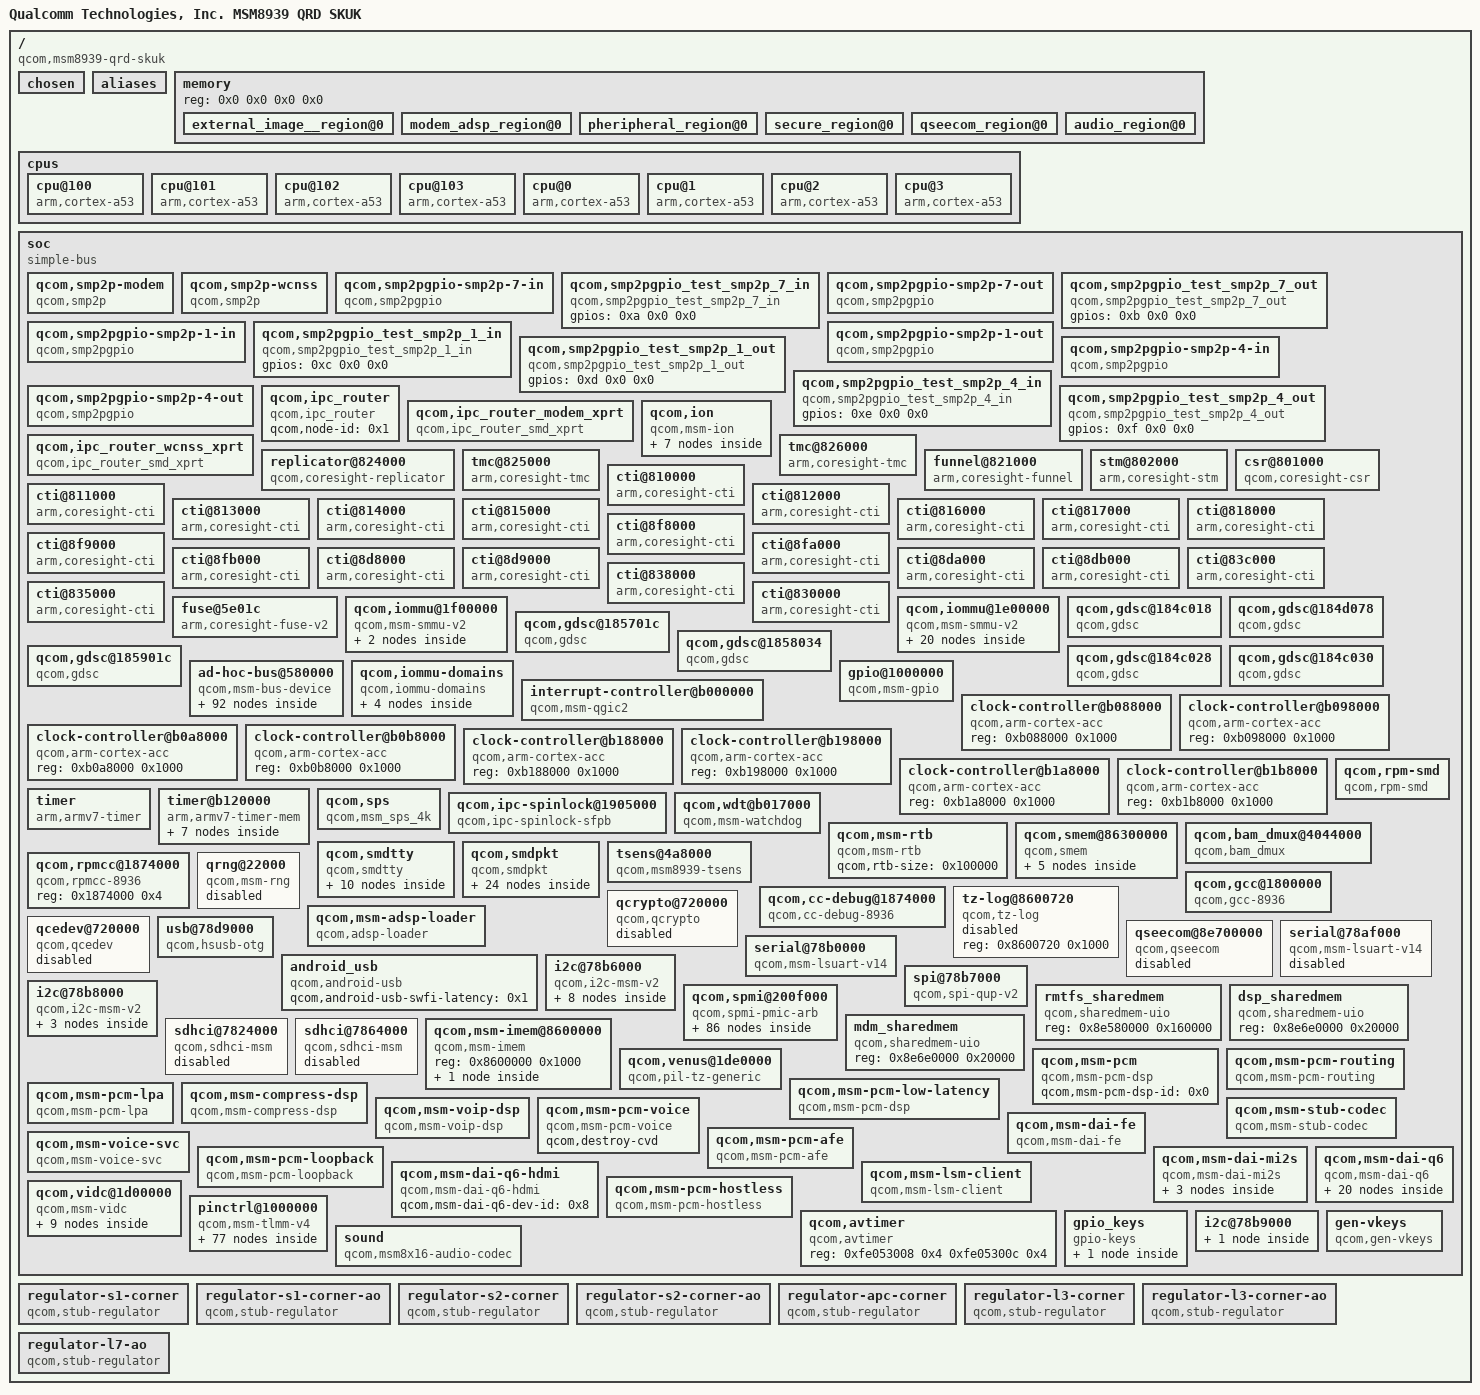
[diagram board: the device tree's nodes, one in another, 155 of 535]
/dts-v1/;

/ {
	#address-cells = <0x2>;
	#size-cells = <0x2>;
	model = "Qualcomm Technologies, Inc. MSM8939 QRD SKUK";
	compatible = "qcom,msm8939-qrd-skuk", "qcom,msm8939-qrd", "qcom,msm8939", "qcom,qrd";
	qcom,msm-id = <0xef 0x0 0xf1 0x0>;
	interrupt-parent = <0x1>;
	qcom,board-id = <0x1000b 0x5>;

	chosen {
	};

	aliases {
		sdhc1 = "/soc/sdhci@7824000";
		sdhc2 = "/soc/sdhci@7864000";
		smd1 = "/soc/qcom,smdtty/qcom,smdtty-apps-fm";
		smd2 = "/soc/qcom,smdtty/smdtty-apps-riva-bt-acl";
		smd3 = "/soc/qcom,smdtty/qcom,smdtty-apps-riva-bt-cmd";
		smd5 = "/soc/qcom,smdtty/smdtty-apps-riva-ant-cmd";
		smd6 = "/soc/qcom,smdtty/smdtty-apps-riva-ant-data";
		smd7 = "/soc/qcom,smdtty/qcom,smdtty-data1";
		smd8 = "/soc/qcom,smdtty/qcom,smdtty-data4";
		smd11 = "/soc/qcom,smdtty/qcom,smdtty-data11";
		smd21 = "/soc/qcom,smdtty/qcom,smdtty-data21";
		smd36 = "/soc/qcom,smdtty/smdtty-loopback";
		i2c0 = "/soc/i2c@78b6000";
		i2c4 = "/soc/i2c@78b8000";
		spi0 = "/soc/spi@78b7000";
	};

	memory {
		device_type = "memory";
		reg = <0x0 0x0 0x0 0x0>;
		#address-cells = <0x2>;
		#size-cells = <0x2>;

		external_image__region@0 {
			linux,reserve-contiguous-region;
			linux,reserve-region;
			linux,remove-completely;
			reg = <0x0 0x8e200000 0x0 0x800000>;
			label = "external_image_mem";
		};

		modem_adsp_region@0 {
			linux,reserve-contiguous-region;
			linux,reserve-region;
			linux,remove-completely;
			reg = <0x0 0x88800000 0x0 0x5a00000>;
			label = "modem_adsp_mem";
			linux,phandle = <0x14>;
			phandle = <0x14>;
		};

		pheripheral_region@0 {
			linux,reserve-contiguous-region;
			linux,reserve-region;
			linux,remove-completely;
			reg = <0x0 0x8ea00000 0x0 0xb00000>;
			label = "peripheral_mem";
			linux,phandle = <0x13>;
			phandle = <0x13>;
		};

		secure_region@0 {
			linux,reserve-contiguous-region;
			reg = <0x0 0x0 0x0 0x6d00000>;
			label = "secure_mem";
			linux,phandle = <0x10>;
			phandle = <0x10>;
		};

		qseecom_region@0 {
			linux,reserve-contiguous-region;
			reg = <0x0 0x0 0x0 0xd00000>;
			label = "qseecom_mem";
			linux,phandle = <0x11>;
			phandle = <0x11>;
		};

		audio_region@0 {
			linux,reserve-contiguous-region;
			reg = <0x0 0x0 0x0 0x314000>;
			label = "audio_mem";
			linux,phandle = <0x12>;
			phandle = <0x12>;
		};
	};

	cpus {
		#address-cells = <0x1>;
		#size-cells = <0x0>;

		cpu@100 {
			device_type = "cpu";
			compatible = "arm,cortex-a53";
			reg = <0x100>;
			enable-method = "qcom,arm-cortex-acc";
			qcom,acc = <0x2>;
		};

		cpu@101 {
			device_type = "cpu";
			compatible = "arm,cortex-a53";
			reg = <0x101>;
			enable-method = "qcom,arm-cortex-acc";
			qcom,acc = <0x3>;
		};

		cpu@102 {
			device_type = "cpu";
			compatible = "arm,cortex-a53";
			reg = <0x102>;
			enable-method = "qcom,arm-cortex-acc";
			qcom,acc = <0x4>;
		};

		cpu@103 {
			device_type = "cpu";
			compatible = "arm,cortex-a53";
			reg = <0x103>;
			enable-method = "qcom,arm-cortex-acc";
			qcom,acc = <0x5>;
		};

		cpu@0 {
			device_type = "cpu";
			compatible = "arm,cortex-a53";
			reg = <0x0>;
			enable-method = "qcom,arm-cortex-acc";
			qcom,acc = <0x6>;
		};

		cpu@1 {
			device_type = "cpu";
			compatible = "arm,cortex-a53";
			reg = <0x1>;
			enable-method = "qcom,arm-cortex-acc";
			qcom,acc = <0x7>;
		};

		cpu@2 {
			device_type = "cpu";
			compatible = "arm,cortex-a53";
			reg = <0x2>;
			enable-method = "qcom,arm-cortex-acc";
			qcom,acc = <0x8>;
		};

		cpu@3 {
			device_type = "cpu";
			compatible = "arm,cortex-a53";
			reg = <0x3>;
			enable-method = "qcom,arm-cortex-acc";
			qcom,acc = <0x9>;
		};
	};

	soc {
		#address-cells = <0x1>;
		#size-cells = <0x1>;
		ranges = <0x0 0x0 0x0 0xffffffff>;
		compatible = "simple-bus";

		qcom,smp2p-modem {
			compatible = "qcom,smp2p";
			reg = <0xb111008 0x4>;
			qcom,remote-pid = <0x1>;
			qcom,irq-bitmask = <0x4000>;
			interrupts = <0x0 0x1b 0x1>;
		};

		qcom,smp2p-wcnss {
			compatible = "qcom,smp2p";
			reg = <0xb111008 0x4>;
			qcom,remote-pid = <0x4>;
			qcom,irq-bitmask = <0x40000>;
			interrupts = <0x0 0x8f 0x1>;
		};

		qcom,smp2pgpio-smp2p-7-in {
			compatible = "qcom,smp2pgpio";
			qcom,entry-name = "smp2p";
			qcom,remote-pid = <0x7>;
			qcom,is-inbound;
			gpio-controller;
			#gpio-cells = <0x2>;
			interrupt-controller;
			#interrupt-cells = <0x2>;
			linux,phandle = <0xa>;
			phandle = <0xa>;
		};

		qcom,smp2pgpio_test_smp2p_7_in {
			compatible = "qcom,smp2pgpio_test_smp2p_7_in";
			gpios = <0xa 0x0 0x0>;
		};

		qcom,smp2pgpio-smp2p-7-out {
			compatible = "qcom,smp2pgpio";
			qcom,entry-name = "smp2p";
			qcom,remote-pid = <0x7>;
			gpio-controller;
			#gpio-cells = <0x2>;
			interrupt-controller;
			#interrupt-cells = <0x2>;
			linux,phandle = <0xb>;
			phandle = <0xb>;
		};

		qcom,smp2pgpio_test_smp2p_7_out {
			compatible = "qcom,smp2pgpio_test_smp2p_7_out";
			gpios = <0xb 0x0 0x0>;
		};

		qcom,smp2pgpio-smp2p-1-in {
			compatible = "qcom,smp2pgpio";
			qcom,entry-name = "smp2p";
			qcom,remote-pid = <0x1>;
			qcom,is-inbound;
			gpio-controller;
			#gpio-cells = <0x2>;
			interrupt-controller;
			#interrupt-cells = <0x2>;
			linux,phandle = <0xc>;
			phandle = <0xc>;
		};

		qcom,smp2pgpio_test_smp2p_1_in {
			compatible = "qcom,smp2pgpio_test_smp2p_1_in";
			gpios = <0xc 0x0 0x0>;
		};

		qcom,smp2pgpio-smp2p-1-out {
			compatible = "qcom,smp2pgpio";
			qcom,entry-name = "smp2p";
			qcom,remote-pid = <0x1>;
			gpio-controller;
			#gpio-cells = <0x2>;
			interrupt-controller;
			#interrupt-cells = <0x2>;
			linux,phandle = <0xd>;
			phandle = <0xd>;
		};

		qcom,smp2pgpio_test_smp2p_1_out {
			compatible = "qcom,smp2pgpio_test_smp2p_1_out";
			gpios = <0xd 0x0 0x0>;
		};

		qcom,smp2pgpio-smp2p-4-in {
			compatible = "qcom,smp2pgpio";
			qcom,entry-name = "smp2p";
			qcom,remote-pid = <0x4>;
			qcom,is-inbound;
			gpio-controller;
			#gpio-cells = <0x2>;
			interrupt-controller;
			#interrupt-cells = <0x2>;
			linux,phandle = <0xe>;
			phandle = <0xe>;
		};

		qcom,smp2pgpio_test_smp2p_4_in {
			compatible = "qcom,smp2pgpio_test_smp2p_4_in";
			gpios = <0xe 0x0 0x0>;
		};

		qcom,smp2pgpio-smp2p-4-out {
			compatible = "qcom,smp2pgpio";
			qcom,entry-name = "smp2p";
			qcom,remote-pid = <0x4>;
			gpio-controller;
			#gpio-cells = <0x2>;
			interrupt-controller;
			#interrupt-cells = <0x2>;
			linux,phandle = <0xf>;
			phandle = <0xf>;
		};

		qcom,smp2pgpio_test_smp2p_4_out {
			compatible = "qcom,smp2pgpio_test_smp2p_4_out";
			gpios = <0xf 0x0 0x0>;
		};

		qcom,ipc_router {
			compatible = "qcom,ipc_router";
			qcom,node-id = <0x1>;
		};

		qcom,ipc_router_modem_xprt {
			compatible = "qcom,ipc_router_smd_xprt";
			qcom,ch-name = "IPCRTR";
			qcom,xprt-remote = "modem";
			qcom,xprt-linkid = <0x1>;
			qcom,xprt-version = <0x1>;
			qcom,fragmented-data;
		};

		qcom,ipc_router_wcnss_xprt {
			compatible = "qcom,ipc_router_smd_xprt";
			qcom,ch-name = "IPCRTR";
			qcom,xprt-remote = "wcnss";
			qcom,xprt-linkid = <0x1>;
			qcom,xprt-version = <0x1>;
			qcom,fragmented-data;
		};

		qcom,ion {
			compatible = "qcom,msm-ion";
			#address-cells = <0x1>;
			#size-cells = <0x0>;

			qcom,ion-heap@25 {
				reg = <0x19>;
				qcom,ion-heap-type = "SYSTEM";
			};

			qcom,ion-heap@21 {
				reg = <0x15>;
				qcom,ion-heap-type = "SYSTEM_CONTIG";
			};

			qcom,ion-heap@8 {
				compatible = "qcom,msm-ion-reserve";
				reg = <0x8>;
				qcom,heap-align = <0x1000>;
				linux,contiguous-region = <0x10>;
				qcom,ion-heap-type = "SECURE_DMA";
			};

			qcom,ion-heap@27 {
				compatible = "qcom,msm-ion-reserve";
				reg = <0x1b>;
				linux,contiguous-region = <0x11>;
				qcom,ion-heap-type = "DMA";
			};

			qcom,ion-heap@28 {
				compatible = "qcom,msm-ion-reserve";
				reg = <0x1c>;
				linux,contiguous-region = <0x12>;
				qcom,ion-heap-type = "DMA";
			};

			qcom,ion-heap@23 {
				compatible = "qcom,msm-ion-reserve";
				reg = <0x17>;
				linux,contiguous-region = <0x13>;
				qcom,ion-heap-type = "DMA";
			};

			qcom,ion-heap@26 {
				compatible = "qcom,msm-ion-reserve";
				reg = <0x1a>;
				linux,contiguous-region = <0x14>;
				qcom,ion-heap-type = "DMA";
			};
		};

		tmc@826000 {
			compatible = "arm,coresight-tmc";
			reg = <0x826000 0x1000 0x884000 0x15000>;
			reg-names = "tmc-base", "bam-base";
			interrupts = <0x0 0xa6 0x0>;
			interrupt-names = "byte-cntr-irq";
			qcom,memory-size = <0x100000>;
			coresight-id = <0x0>;
			coresight-name = "coresight-tmc-etr";
			coresight-nr-inports = <0x1>;
			coresight-ctis = <0x15 0x16>;
			clocks = <0x17 0x1492202a 0x17 0xdd121669>;
			clock-names = "core_clk", "core_a_clk";
			linux,phandle = <0x18>;
			phandle = <0x18>;
		};

		replicator@824000 {
			compatible = "qcom,coresight-replicator";
			reg = <0x824000 0x1000>;
			reg-names = "replicator-base";
			coresight-id = <0x1>;
			coresight-name = "coresight-replicator";
			coresight-nr-inports = <0x1>;
			coresight-outports = <0x0>;
			coresight-child-list = <0x18>;
			coresight-child-ports = <0x0>;
			clocks = <0x17 0x1492202a 0x17 0xdd121669>;
			clock-names = "core_clk", "core_a_clk";
			linux,phandle = <0x19>;
			phandle = <0x19>;
		};

		tmc@825000 {
			compatible = "arm,coresight-tmc";
			reg = <0x825000 0x1000>;
			reg-names = "tmc-base";
			coresight-id = <0x2>;
			coresight-name = "coresight-tmc-etf";
			coresight-nr-inports = <0x1>;
			coresight-outports = <0x0>;
			coresight-child-list = <0x19>;
			coresight-child-ports = <0x0>;
			coresight-default-sink;
			coresight-ctis = <0x15 0x16>;
			clocks = <0x17 0x1492202a 0x17 0xdd121669>;
			clock-names = "core_clk", "core_a_clk";
			linux,phandle = <0x1a>;
			phandle = <0x1a>;
		};

		funnel@821000 {
			compatible = "arm,coresight-funnel";
			reg = <0x821000 0x1000>;
			reg-names = "funnel-base";
			coresight-id = <0x3>;
			coresight-name = "coresight-funnel-in0";
			coresight-nr-inports = <0x8>;
			coresight-outports = <0x0>;
			coresight-child-list = <0x1a>;
			coresight-child-ports = <0x0>;
			clocks = <0x17 0x1492202a 0x17 0xdd121669>;
			clock-names = "core_clk", "core_a_clk";
			linux,phandle = <0x1b>;
			phandle = <0x1b>;
		};

		stm@802000 {
			compatible = "arm,coresight-stm";
			reg = <0x802000 0x1000 0x9280000 0x180000>;
			reg-names = "stm-base", "stm-data-base";
			coresight-id = <0x4>;
			coresight-name = "coresight-stm";
			coresight-nr-inports = <0x0>;
			coresight-outports = <0x0>;
			coresight-child-list = <0x1b>;
			coresight-child-ports = <0x7>;
			clocks = <0x17 0x1492202a 0x17 0xdd121669>;
			clock-names = "core_clk", "core_a_clk";
		};

		csr@801000 {
			compatible = "qcom,coresight-csr";
			reg = <0x801000 0x1000>;
			reg-names = "csr-base";
			coresight-id = <0x5>;
			coresight-name = "coresight-csr";
			coresight-nr-inports = <0x0>;
			qcom,blk-size = <0x1>;
		};

		cti@810000 {
			compatible = "arm,coresight-cti";
			reg = <0x810000 0x1000>;
			reg-names = "cti-base";
			coresight-id = <0x6>;
			coresight-name = "coresight-cti0";
			coresight-nr-inports = <0x0>;
			clocks = <0x17 0x1492202a 0x17 0xdd121669>;
			clock-names = "core_clk", "core_a_clk";
			linux,phandle = <0x15>;
			phandle = <0x15>;
		};

		cti@811000 {
			compatible = "arm,coresight-cti";
			reg = <0x811000 0x1000>;
			reg-names = "cti-base";
			coresight-id = <0x7>;
			coresight-name = "coresight-cti1";
			coresight-nr-inports = <0x0>;
			clocks = <0x17 0x1492202a 0x17 0xdd121669>;
			clock-names = "core_clk", "core_a_clk";
		};

		cti@812000 {
			compatible = "arm,coresight-cti";
			reg = <0x812000 0x1000>;
			reg-names = "cti-base";
			coresight-id = <0x8>;
			coresight-name = "coresight-cti2";
			coresight-nr-inports = <0x0>;
			clocks = <0x17 0x1492202a 0x17 0xdd121669>;
			clock-names = "core_clk", "core_a_clk";
		};

		cti@813000 {
			compatible = "arm,coresight-cti";
			reg = <0x813000 0x1000>;
			reg-names = "cti-base";
			coresight-id = <0x9>;
			coresight-name = "coresight-cti3";
			coresight-nr-inports = <0x0>;
			clocks = <0x17 0x1492202a 0x17 0xdd121669>;
			clock-names = "core_clk", "core_a_clk";
		};

		cti@814000 {
			compatible = "arm,coresight-cti";
			reg = <0x814000 0x1000>;
			reg-names = "cti-base";
			coresight-id = <0xa>;
			coresight-name = "coresight-cti4";
			coresight-nr-inports = <0x0>;
			clocks = <0x17 0x1492202a 0x17 0xdd121669>;
			clock-names = "core_clk", "core_a_clk";
		};

		cti@815000 {
			compatible = "arm,coresight-cti";
			reg = <0x815000 0x1000>;
			reg-names = "cti-base";
			coresight-id = <0xb>;
			coresight-name = "coresight-cti5";
			coresight-nr-inports = <0x0>;
			clocks = <0x17 0x1492202a 0x17 0xdd121669>;
			clock-names = "core_clk", "core_a_clk";
		};

		cti@816000 {
			compatible = "arm,coresight-cti";
			reg = <0x816000 0x1000>;
			reg-names = "cti-base";
			coresight-id = <0xc>;
			coresight-name = "coresight-cti6";
			coresight-nr-inports = <0x0>;
			clocks = <0x17 0x1492202a 0x17 0xdd121669>;
			clock-names = "core_clk", "core_a_clk";
		};

		cti@817000 {
			compatible = "arm,coresight-cti";
			reg = <0x817000 0x1000>;
			reg-names = "cti-base";
			coresight-id = <0xd>;
			coresight-name = "coresight-cti7";
			coresight-nr-inports = <0x0>;
			clocks = <0x17 0x1492202a 0x17 0xdd121669>;
			clock-names = "core_clk", "core_a_clk";
		};

		cti@818000 {
			compatible = "arm,coresight-cti";
			reg = <0x818000 0x1000>;
			reg-names = "cti-base";
			coresight-id = <0xe>;
			coresight-name = "coresight-cti8";
			coresight-nr-inports = <0x0>;
			clocks = <0x17 0x1492202a 0x17 0xdd121669>;
			clock-names = "core_clk", "core_a_clk";
			linux,phandle = <0x16>;
			phandle = <0x16>;
		};

		cti@8f8000 {
			compatible = "arm,coresight-cti";
			reg = <0x8f8000 0x1000>;
			reg-names = "cti-base";
			coresight-id = <0xf>;
			coresight-name = "coresight-cti-perf-cpu0";
			coresight-nr-inports = <0x0>;
			clocks = <0x17 0x1492202a 0x17 0xdd121669>;
			clock-names = "core_clk", "core_a_clk";
		};

		cti@8f9000 {
			compatible = "arm,coresight-cti";
			reg = <0x8f9000 0x1000>;
			reg-names = "cti-base";
			coresight-id = <0x10>;
			coresight-name = "coresight-cti-perf-cpu1";
			coresight-nr-inports = <0x0>;
			clocks = <0x17 0x1492202a 0x17 0xdd121669>;
			clock-names = "core_clk", "core_a_clk";
		};

		cti@8fa000 {
			compatible = "arm,coresight-cti";
			reg = <0x8fa000 0x1000>;
			reg-names = "cti-base";
			coresight-id = <0x11>;
			coresight-name = "coresight-cti-perf-cpu2";
			coresight-nr-inports = <0x0>;
			clocks = <0x17 0x1492202a 0x17 0xdd121669>;
			clock-names = "core_clk", "core_a_clk";
		};

		cti@8fb000 {
			compatible = "arm,coresight-cti";
			reg = <0x8fb000 0x1000>;
			reg-names = "cti-base";
			coresight-id = <0x12>;
			coresight-name = "coresight-cti-perf-cpu3";
			coresight-nr-inports = <0x0>;
			clocks = <0x17 0x1492202a 0x17 0xdd121669>;
			clock-names = "core_clk", "core_a_clk";
		};

		cti@8d8000 {
			compatible = "arm,coresight-cti";
			reg = <0x8d8000 0x1000>;
			reg-names = "cti-base";
			coresight-id = <0x13>;
			coresight-name = "coresight-cti-pow-cpu0";
			coresight-nr-inports = <0x0>;
			clocks = <0x17 0x1492202a 0x17 0xdd121669>;
			clock-names = "core_clk", "core_a_clk";
		};

		cti@8d9000 {
			compatible = "arm,coresight-cti";
			reg = <0x8d9000 0x1000>;
			reg-names = "cti-base";
			coresight-id = <0x14>;
			coresight-name = "coresight-cti-pow-cpu1";
			coresight-nr-inports = <0x0>;
			clocks = <0x17 0x1492202a 0x17 0xdd121669>;
			clock-names = "core_clk", "core_a_clk";
		};

		cti@8da000 {
			compatible = "arm,coresight-cti";
			reg = <0x8da000 0x1000>;
			reg-names = "cti-base";
			coresight-id = <0x15>;
			coresight-name = "coresight-cti-pow-cpu2";
			coresight-nr-inports = <0x0>;
			clocks = <0x17 0x1492202a 0x17 0xdd121669>;
			clock-names = "core_clk", "core_a_clk";
		};

		cti@8db000 {
			compatible = "arm,coresight-cti";
			reg = <0x8db000 0x1000>;
			reg-names = "cti-base";
			coresight-id = <0x16>;
			coresight-name = "coresight-cti-pow-cpu3";
			coresight-nr-inports = <0x0>;
			clocks = <0x17 0x1492202a 0x17 0xdd121669>;
			clock-names = "core_clk", "core_a_clk";
		};

		cti@83c000 {
			compatible = "arm,coresight-cti";
			reg = <0x83c000 0x1000>;
			reg-names = "cti-base";
			coresight-id = <0x17>;
			coresight-name = "coresight-cti-rpm-cpu0";
			coresight-nr-inports = <0x0>;
			clocks = <0x17 0x1492202a 0x17 0xdd121669>;
			clock-names = "core_clk", "core_a_clk";
		};

		cti@838000 {
			compatible = "arm,coresight-cti";
			reg = <0x838000 0x1000>;
			reg-names = "cti-base";
			coresight-id = <0x18>;
			coresight-name = "coresight-cti-modem-cpu0";
			coresight-nr-inports = <0x0>;
			clocks = <0x17 0x1492202a 0x17 0xdd121669>;
			clock-names = "core_clk", "core_a_clk";
		};

		cti@835000 {
			compatible = "arm,coresight-cti";
			reg = <0x835000 0x1000>;
			reg-names = "cti-base";
			coresight-id = <0x19>;
			coresight-name = "coresight-cti-wcn-cpu0";
			coresight-nr-inports = <0x0>;
			clocks = <0x17 0x1492202a 0x17 0xdd121669>;
			clock-names = "core_clk", "core_a_clk";
		};

		cti@830000 {
			compatible = "arm,coresight-cti";
			reg = <0x830000 0x1000>;
			reg-names = "cti-base";
			coresight-id = <0x1a>;
			coresight-name = "coresight-cti-video-cpu0";
			coresight-nr-inports = <0x0>;
			clocks = <0x17 0x1492202a 0x17 0xdd121669>;
			clock-names = "core_clk", "core_a_clk";
		};

		fuse@5e01c {
			compatible = "arm,coresight-fuse-v2";
			reg = <0x5e01c 0x8>;
			reg-names = "fuse-base";
			coresight-id = <0x1b>;
			coresight-name = "coresight-fuse";
			coresight-nr-inports = <0x0>;
		};

		qcom,iommu@1f00000 {
			compatible = "qcom,msm-smmu-v2", "qcom,msm-mmu-500";
			#address-cells = <0x1>;
			#size-cells = <0x1>;
			ranges;
			reg = <0x1f00000 0x10000>;
			reg-names = "iommu_base";
			interrupts = <0x0 0x2b 0x0 0x0 0x2a 0x0>;
			interrupt-names = "global_cfg_NS_irq", "global_cfg_S_irq";
			label = "gfx_iommu";
			qcom,iommu-secure-id = <0x12>;
			clocks = <0x1c 0x75eaefa5 0x1c 0x59505e55>;
			clock-names = "iface_clk", "core_clk";
			status = "ok";

			qcom,iommu-ctx@1f09000 {
				compatible = "qcom,msm-smmu-v2-ctx";
				reg = <0x1f09000 0x1000>;
				interrupts = <0x0 0xf1 0x0>;
				qcom,iommu-ctx-sids = <0x0>;
				label = "gfx3d_user";
			};

			qcom,iommu-ctx@1f0a000 {
				compatible = "qcom,msm-smmu-v2-ctx";
				reg = <0x1f0a000 0x1000>;
				interrupts = <0x0 0xf2 0x0>;
				qcom,iommu-ctx-sids = <0x1>;
				label = "gfx3d_priv";
			};
		};

		qcom,iommu@1e00000 {
			compatible = "qcom,msm-smmu-v2", "qcom,msm-mmu-500";
			#address-cells = <0x1>;
			#size-cells = <0x1>;
			ranges;
			reg = <0x1e00000 0x40000>;
			reg-names = "iommu_base";
			interrupts = <0x0 0x2b 0x0 0x0 0x2a 0x0>;
			interrupt-names = "global_cfg_NS_irq", "global_cfg_S_irq";
			label = "apps_iommu";
			qcom,iommu-secure-id = <0x11>;
			clocks = <0x1c 0x75eaefa5 0x1c 0xaf56a329>;
			clock-names = "iface_clk", "core_clk";
			qcom,cb-base-offset = <0x20000>;
			status = "ok";

			qcom,iommu-ctx@1e22000 {
				compatible = "qcom,msm-smmu-v2-ctx";
				reg = <0x1e22000 0x1000>;
				interrupts = <0x0 0x35 0x0>;
				qcom,iommu-ctx-sids = <0x2000>;
				label = "jpeg_enc0";
			};

			qcom,iommu-ctx@1e23000 {
				compatible = "qcom,msm-smmu-v2-ctx";
				reg = <0x1e23000 0x1000>;
				interrupts = <0x0 0x36 0x0>;
				qcom,iommu-ctx-sids = <0x400>;
				label = "vfe";
			};

			qcom,iommu-ctx@1e24000 {
				compatible = "qcom,msm-smmu-v2-ctx";
				reg = <0x1e24000 0x1000>;
				interrupts = <0x0 0x3a 0x0>;
				qcom,iommu-ctx-sids = <0xc00 0x2800>;
				label = "mdp_0";
			};

			qcom,iommu-ctx@1e25000 {
				compatible = "qcom,msm-smmu-v2-ctx";
				reg = <0x1e25000 0x1000>;
				interrupts = <0x0 0x3c 0x0>;
				qcom,iommu-ctx-sids = <0x800 0x801 0x802 0x803 0x804 0x805 0x807>;
				label = "venus_ns";
				linux,phandle = <0x62>;
				phandle = <0x62>;
			};

			qcom,iommu-ctx@1e26000 {
				compatible = "qcom,msm-smmu-v2-ctx";
				reg = <0x1e26000 0x1000>;
				interrupts = <0x0 0x3d 0x0>;
				qcom,iommu-ctx-sids = <0x2400>;
				label = "cpp";
			};

			qcom,iommu-ctx@1e27000 {
				compatible = "qcom,msm-smmu-v2-ctx";
				reg = <0x1e27000 0x1000>;
				interrupts = <0x0 0x4c 0x0>;
				qcom,iommu-ctx-sids = <0x1000>;
				label = "mDSP";
			};

			qcom,iommu-ctx@1e28000 {
				compatible = "qcom,msm-smmu-v2-ctx";
				reg = <0x1e28000 0x1000>;
				interrupts = <0x0 0x4d 0x0>;
				qcom,iommu-ctx-sids = <0x1400>;
				label = "gss";
			};

			qcom,iommu-ctx@1e29000 {
				compatible = "qcom,msm-smmu-v2-ctx";
				reg = <0x1e29000 0x1000>;
				interrupts = <0x0 0x50 0x0>;
				qcom,iommu-ctx-sids = <0x1800>;
				label = "a2";
			};

			qcom,iommu-ctx@1e32000 {
				compatible = "qcom,msm-smmu-v2-ctx";
				qcom,secure-context;
				reg = <0x1e32000 0x1000>;
				interrupts = <0x0 0x6e 0x0 0x0 0x6e 0x0>;
				qcom,iommu-ctx-sids = <0xc01 0x2801>;
				label = "mdp_1";
			};

			qcom,iommu-ctx@1e33000 {
				compatible = "qcom,msm-smmu-v2-ctx";
				qcom,secure-context;
				reg = <0x1e33000 0x1000>;
				interrupts = <0x0 0x6f 0x0 0x0 0x6f 0x0>;
				qcom,iommu-ctx-sids = <0x885>;
				label = "venus_sec_pixel";
				linux,phandle = <0x64>;
				phandle = <0x64>;
			};

			qcom,iommu-ctx@1e34000 {
				compatible = "qcom,msm-smmu-v2-ctx";
				qcom,secure-context;
				reg = <0x1e34000 0x1000>;
				interrupts = <0x0 0x70 0x0 0x0 0x70 0x0>;
				qcom,iommu-ctx-sids = <0x880 0x881 0x882 0x883 0x884>;
				label = "venus_sec_bitstream";
				linux,phandle = <0x63>;
				phandle = <0x63>;
			};

			qcom,iommu-ctx@1e35000 {
				compatible = "qcom,msm-smmu-v2-ctx";
				qcom,secure-context;
				reg = <0x1e35000 0x1000>;
				interrupts = <0x0 0x71 0x0 0x0 0x71 0x0>;
				qcom,iommu-ctx-sids = <0x887 0x8a0>;
				label = "venus_sec_non_pixel";
				linux,phandle = <0x65>;
				phandle = <0x65>;
			};

			qcom,iommu-ctx@1e36000 {
				compatible = "qcom,msm-smmu-v2-ctx";
				qcom,secure-context;
				reg = <0x1e36000 0x1000>;
				interrupts = <0x0 0x72 0x0 0x0 0x72 0x0>;
				qcom,iommu-ctx-sids = <0x8c0 0x8c6>;
				label = "venus_fw";
			};

			qcom,iommu-ctx@1e37000 {
				compatible = "qcom,msm-smmu-v2-ctx";
				qcom,secure-context;
				reg = <0x1e37000 0x1000>;
				interrupts = <0x0 0x73 0x0 0x0 0x73 0x0>;
				qcom,iommu-ctx-sids = <0x40>;
				label = "periph_rpm";
			};

			qcom,iommu-ctx@1e38000 {
				compatible = "qcom,msm-smmu-v2-ctx";
				reg = <0x1e38000 0x1000>;
				interrupts = <0x0 0x74 0x0>;
				qcom,iommu-ctx-sids = <0xc0 0xc4 0xc8 0xcc 0xd0 0xd3 0xd4 0xd7 0xd8 0xdb 0xdc 0xdf 0xf0 0xf3 0xf4 0xf7 0xf8 0xfb 0xfc 0xff>;
				label = "periph_CE";
			};

			qcom,iommu-ctx@1e39000 {
				compatible = "qcom,msm-smmu-v2-ctx";
				reg = <0x1e39000 0x1000>;
				interrupts = <0x0 0x75 0x0>;
				qcom,iommu-ctx-sids = <0x280 0x283 0x284 0x287 0x288 0x28b 0x28c 0x28f 0x290 0x293 0x294 0x297 0x298 0x29b 0x29c 0x29f>;
				label = "periph_BLSP";
			};

			qcom,iommu-ctx@1e3a000 {
				compatible = "qcom,msm-smmu-v2-ctx";
				reg = <0x1e3a000 0x1000>;
				interrupts = <0x0 0x76 0x0>;
				qcom,iommu-ctx-sids = <0x100>;
				label = "periph_SDC1";
			};

			qcom,iommu-ctx@1e3b000 {
				compatible = "qcom,msm-smmu-v2-ctx";
				reg = <0x1e3b000 0x1000>;
				interrupts = <0x0 0x77 0x0>;
				qcom,iommu-ctx-sids = <0x140>;
				label = "periph_SDC2";
			};

			qcom,iommu-ctx@1e3c000 {
				compatible = "qcom,msm-smmu-v2-ctx";
				reg = <0x1e3c000 0x1000>;
				interrupts = <0x0 0x78 0x0>;
				qcom,iommu-ctx-sids = <0x1c0>;
				label = "periph_audio";
			};

			qcom,iommu-ctx@1e3d000 {
				compatible = "qcom,msm-smmu-v2-ctx";
				reg = <0x1e3d000 0x1000>;
				interrupts = <0x0 0x79 0x0>;
				qcom,iommu-ctx-sids = <0x2c0>;
				label = "periph_USB_HS1";
			};
		};

		qcom,gdsc@184c018 {
			compatible = "qcom,gdsc";
			regulator-name = "gdsc_venus";
			reg = <0x184c018 0x4>;
			status = "okay";
			linux,phandle = <0x88>;
			phandle = <0x88>;
		};

		qcom,gdsc@184d078 {
			compatible = "qcom,gdsc";
			regulator-name = "gdsc_mdss";
			reg = <0x184d078 0x4>;
			status = "okay";
		};

		qcom,gdsc@185701c {
			compatible = "qcom,gdsc";
			regulator-name = "gdsc_jpeg";
			reg = <0x185701c 0x4>;
			status = "okay";
		};

		qcom,gdsc@1858034 {
			compatible = "qcom,gdsc";
			regulator-name = "gdsc_vfe";
			reg = <0x1858034 0x4>;
			status = "okay";
		};

		qcom,gdsc@185901c {
			compatible = "qcom,gdsc";
			regulator-name = "gdsc_oxili_gx";
			reg = <0x185901c 0x4>;
			status = "okay";
		};

		qcom,gdsc@184c028 {
			compatible = "qcom,gdsc";
			regulator-name = "gdsc_venus_core0";
			reg = <0x184c028 0x4>;
			status = "okay";
			linux,phandle = <0x89>;
			phandle = <0x89>;
		};

		qcom,gdsc@184c030 {
			compatible = "qcom,gdsc";
			regulator-name = "gdsc_venus_core1";
			reg = <0x184c030 0x4>;
			status = "okay";
			linux,phandle = <0x8a>;
			phandle = <0x8a>;
		};

		ad-hoc-bus@580000 {
			compatible = "qcom,msm-bus-device";
			reg = <0x580000 0x14000 0x580000 0x14000 0x400000 0x62000 0x500000 0x11000>;
			reg-names = "snoc-base", "snoc-mm-base", "bimc-base", "pnoc-base";

			fab-snoc {
				cell-id = <0x400>;
				label = "fab-snoc";
				qcom,fab-dev;
				qcom,bypass-qos-prg;
				qcom,base-name = "snoc-base";
				qcom,base-offset = <0x7000>;
				qcom,qos-off = <0x1000>;
				qcom,bus-type = <0x1>;
				clock-names = "bus_clk", "bus_a_clk";
				clocks = <0x17 0xe6900bb6 0x17 0x5d4683bd>;
				linux,phandle = <0x25>;
				phandle = <0x25>;
			};

			fab-snoc-mm {
				cell-id = <0x800>;
				label = "fab-snoc-mm";
				qcom,fab-dev;
				qcom,bypass-qos-prg;
				qcom,base-name = "snoc-mm-base";
				qcom,base-offset = <0x7000>;
				qcom,qos-off = <0x1000>;
				qcom,bus-type = <0x1>;
				clock-names = "bus_clk", "bus_a_clk";
				clocks = <0x17 0xd61e5721 0x17 0x50600f1b>;
				linux,phandle = <0x1f>;
				phandle = <0x1f>;
			};

			fab-bimc {
				cell-id = <0x0>;
				label = "fab-bimc";
				qcom,fab-dev;
				qcom,bypass-qos-prg;
				qcom,base-name = "bimc-base";
				qcom,bus-type = <0x2>;
				clock-names = "bus_clk", "bus_a_clk";
				clocks = <0x17 0xd212feea 0x17 0x71d1a499>;
				linux,phandle = <0x35>;
				phandle = <0x35>;
			};

			fab-pnoc {
				cell-id = <0x1000>;
				label = "fab-pnoc";
				qcom,fab-dev;
				qcom,bypass-qos-prg;
				qcom,base-name = "pnoc-base";
				qcom,base-offset = <0x7000>;
				qcom,qos-delta = <0x1000>;
				qcom,bus-type = <0x1>;
				clock-names = "bus_clk", "bus_a_clk";
				clocks = <0x17 0x2b53b688 0x17 0x9753a54f>;
				linux,phandle = <0x38>;
				phandle = <0x38>;
			};

			mas-video {
				cell-id = <0x3f>;
				label = "mas-video";
				qcom,qport = <0x8>;
				qcom,ap-owned;
				qcom,connections = <0x1d 0x1e>;
				qcom,bus-dev = <0x1f>;
				qcom,qos-mode = "bypass";
				qcom,buswidth = <0x10>;
			};

			mas-jpeg {
				cell-id = <0x3e>;
				label = "mas-jpeg";
				qcom,ap-owned;
				qcom,qport = <0x6>;
				qcom,connections = <0x1d 0x1e>;
				qcom,bus-dev = <0x1f>;
				qcom,qos-mode = "bypass";
				qcom,buswidth = <0x10>;
			};

			mas-vfe {
				cell-id = <0x1d>;
				label = "mas-vfe";
				qcom,ap-owned;
				qcom,qport = <0x9>;
				qcom,connections = <0x20 0x1e>;
				qcom,bus-dev = <0x1f>;
				qcom,qos-mode = "bypass";
				qcom,buswidth = <0x10>;
			};

			mas-mdp-0 {
				cell-id = <0x16>;
				label = "mas-mdp-0";
				qcom,ap-owned;
				qcom,connections = <0x20 0x1e>;
				qcom,qport = <0x7>;
				qcom,bus-dev = <0x1f>;
				qcom,qos-mode = "bypass";
				qcom,buswidth = <0x10>;
			};

			mas-mdp-1 {
				cell-id = <0x17>;
				label = "mas-mdp-1";
				qcom,ap-owned;
				qcom,connections = <0x1d 0x1e>;
				qcom,qport = <0x7>;
				qcom,bus-dev = <0x1f>;
				qcom,qos-mode = "bypass";
				qcom,buswidth = <0x10>;
			};

			mas-cpp {
				cell-id = <0x6a>;
				label = "mas-cpp";
				qcom,ap-owned;
				qcom,connections = <0x1d 0x1e>;
				qcom,qport = <0xc>;
				qcom,bus-dev = <0x1f>;
				qcom,qos-mode = "bypass";
				qcom,buswidth = <0x10>;
			};

			mm-int-0 {
				cell-id = <0x2710>;
				label = "mm-int-0";
				qcom,ap-owned;
				qcom,connections = <0x21>;
				qcom,bus-dev = <0x1f>;
				qcom,buswidth = <0x10>;
				linux,phandle = <0x1d>;
				phandle = <0x1d>;
			};

			mm-int-1 {
				cell-id = <0x2711>;
				label = "mm-int-1";
				qcom,ap-owned;
				qcom,connections = <0x22>;
				qcom,bus-dev = <0x1f>;
				qcom,buswidth = <0x10>;
				linux,phandle = <0x20>;
				phandle = <0x20>;
			};

			mm-int-2 {
				cell-id = <0x2712>;
				label = "mm-int-2";
				qcom,ap-owned;
				qcom,connections = <0x23>;
				qcom,bus-dev = <0x1f>;
				qcom,buswidth = <0x10>;
				linux,phandle = <0x1e>;
				phandle = <0x1e>;
			};

			mas-qdss-bam {
				cell-id = <0x35>;
				label = "mas-qdss-bam";
				qcom,connections = <0x24>;
				qcom,ap-owned;
				qcom,qport = <0xb>;
				qcom,bus-dev = <0x25>;
				qom,buswidth = <0x4>;
				qcom,qos-mode = "fixed";
				qcom,prio1 = <0x1>;
				qcom,prio0 = <0x1>;
			};

			mas-snoc-cfg {
				cell-id = <0x36>;
				label = "mas-snoc-cfg";
				qcom,connections = <0x24>;
				qcom,bus-dev = <0x25>;
				qcom,qos-mode = "bypass";
				qom,buswidth = <0x4>;
				qcom,mas-rpm-id = <0x14>;
			};

			mas-qdss-etr {
				cell-id = <0x3c>;
				label = "mas-qdss-etr";
				qcom,connections = <0x24>;
				qcom,ap-owned;
				qcom,qport = <0xa>;
				qcom,bus-dev = <0x25>;
				qcom,qos-mode = "fixed";
				qcom,prio1 = <0x1>;
				qcom,prio0 = <0x1>;
				qom,buswidth = <0x8>;
			};

			snoc-int-0 {
				cell-id = <0x2714>;
				label = "snoc-int-0";
				qcom,connections = <0x26 0x27 0x28>;
				qcom,bus-dev = <0x25>;
				qcom,mas-rpm-id = <0x63>;
				qcom,slv-rpm-id = <0x82>;
				qcom,buswidth = <0x8>;
				linux,phandle = <0x23>;
				phandle = <0x23>;
			};

			snoc-int-1 {
				cell-id = <0x2715>;
				label = "snoc-int-1";
				qcom,connections = <0x29 0x2a 0x2b>;
				qcom,bus-dev = <0x25>;
				qcom,mas-rpm-id = <0x64>;
				qcom,slv-rpm-id = <0x83>;
				qcom,buswidth = <0x8>;
				linux,phandle = <0x30>;
				phandle = <0x30>;
			};

			snoc-int-bmc {
				cell-id = <0x2716>;
				label = "snoc-bimc";
				qcom,connections = <0x22>;
				qcom,bus-dev = <0x25>;
				qcom,mas-rpm-id = <0x65>;
				qcom,slv-rpm-id = <0x84>;
				qcom,buswidth = <0x8>;
				linux,phandle = <0x2f>;
				phandle = <0x2f>;
			};

			snoc-bimc-0-mas {
				cell-id = <0x2717>;
				label = "snoc-bimc-0-mas";
				qcom,connections = <0x2c>;
				qcom,bus-dev = <0x25>;
				qcom,mas-rpm-id = <0x3>;
				qcom,buswidth = <0x8>;
				linux,phandle = <0x22>;
				phandle = <0x22>;
			};

			snoc-bimc-1-mas {
				cell-id = <0x2718>;
				label = "snoc-bimc-1-mas";
				qcom,connections = <0x2d>;
				qcom,bus-dev = <0x25>;
				qcom,ap-owned;
				qcom,buswidth = <0x10>;
			};

			snoc-bimc-2-mas {
				cell-id = <0x273d>;
				label = "snoc-bimc-2-mas";
				qcom,connections = <0x2e>;
				qcom,bus-dev = <0x25>;
				qcom,ap-owned;
				qcom,buswidth = <0x10>;
				linux,phandle = <0x21>;
				phandle = <0x21>;
			};

			qdss-int {
				cell-id = <0x2719>;
				label = "qdss-int";
				qcom,ap-owned;
				qcom,connections = <0x23 0x2f>;
				qcom,bus-dev = <0x25>;
				qcom,buswidth = <0x8>;
				linux,phandle = <0x24>;
				phandle = <0x24>;
			};

			bimc-snoc-slv {
				cell-id = <0x2721>;
				label = "bimc_snoc_slv";
				qcom,ap-owned;
				qcom,connections = <0x23 0x30>;
				qcom,bus-dev = <0x25>;
				qcom,buswidth = <0x8>;
				linux,phandle = <0x36>;
				phandle = <0x36>;
			};

			snoc-pnoc-mas {
				cell-id = <0x2739>;
				label = "snoc-pnoc-mas";
				qcom,connections = <0x31>;
				qcom,bus-dev = <0x25>;
				qcom,buswidth = <0x8>;
				linux,phandle = <0x28>;
				phandle = <0x28>;
			};

			pnoc-snoc-slv {
				cell-id = <0x271b>;
				label = "snoc-pnoc";
				qcom,connections = <0x23 0x2f 0x30>;
				qcom,bus-dev = <0x25>;
				qcom,slv-rpm-id = <0x2d>;
				qcom,buswidth = <0x8>;
				linux,phandle = <0x61>;
				phandle = <0x61>;
			};

			slv-srvc-snoc {
				cell-id = <0x24b>;
				label = "snoc-srvc-snoc";
				qcom,bus-dev = <0x25>;
				qcom,slv-rpm-id = <0x1d>;
				qcom,buswidth = <0x8>;
			};

			slv-qdss-stm {
				cell-id = <0x24c>;
				label = "snoc-qdss-stm";
				qcom,bus-dev = <0x25>;
				qcom,buswidth = <0x4>;
				qcom,slv-rpm-id = <0x1e>;
				linux,phandle = <0x26>;
				phandle = <0x26>;
			};

			slv-imem {
				cell-id = <0x207>;
				label = "slv_imem";
				qcom,bus-dev = <0x25>;
				qcom,buswidth = <0x8>;
				qcom,slv-rpm-id = <0x1a>;
				linux,phandle = <0x27>;
				phandle = <0x27>;
			};

			slv-apss {
				cell-id = <0x205>;
				label = "slv_apss";
				qcom,bus-dev = <0x25>;
				qcom,slv-rpm-id = <0x14>;
				qcom,buswidth = <0x4>;
				linux,phandle = <0x29>;
				phandle = <0x29>;
			};

			slv-cats-0 {
				cell-id = <0x297>;
				label = "slv-cats-0";
				qcom,bus-dev = <0x25>;
				qcom,slv-rpm-id = <0x6a>;
				qcom,buswidth = <0x10>;
				linux,phandle = <0x2a>;
				phandle = <0x2a>;
			};

			slv-cats-1 {
				cell-id = <0x298>;
				label = "slv-cats-1";
				qcom,bus-dev = <0x25>;
				qcom,slv-rpm-id = <0x6b>;
				qcom,buswidth = <0x8>;
				linux,phandle = <0x2b>;
				phandle = <0x2b>;
			};

			mas-apss {
				cell-id = <0x1>;
				label = "mas-apss";
				qcom,ap-owned;
				qcom,connections = <0x32 0x33 0x34>;
				qcom,qport = <0x0>;
				qcom,bus-dev = <0x35>;
				qcom,qos-mode = "fixed";
				qcom,prio-lvl = <0x0>;
				qcom,prio-rd = <0x0>;
				qcom,prio-wr = <0x0>;
				qom,buswidth = <0x8>;
			};

			mas-tcu0 {
				cell-id = <0x68>;
				label = "mas-tcu0";
				qcom,ap-owned;
				qcom,connections = <0x32 0x33 0x34>;
				qcom,qport = <0x5>;
				qcom,bus-dev = <0x35>;
				qcom,qos-mode = "fixed";
				qcom,prio-lvl = <0x2>;
				qcom,prio-rd = <0x2>;
				qcom,prio-wr = <0x2>;
				qom,buswidth = <0x8>;
			};

			mas-tcu1 {
				cell-id = <0x69>;
				label = "mas-tcu1";
				qcom,ap-owned;
				qcom,connections = <0x32 0x33 0x34>;
				qcom,qport = <0x6>;
				qcom,bus-dev = <0x35>;
				qcom,qos-mode = "fixed";
				qcom,prio-lvl = <0x2>;
				qcom,prio-rd = <0x2>;
				qcom,prio-wr = <0x2>;
				qom,buswidth = <0x8>;
			};

			mas-gfx {
				cell-id = <0x1a>;
				label = "mas-gfx";
				qcom,ap-owned;
				qcom,connections = <0x32 0x33 0x34>;
				qcom,qport = <0x2>;
				qcom,bus-dev = <0x35>;
				qcom,qos-mode = "fixed";
				qcom,prio-lvl = <0x0>;
				qcom,prio-rd = <0x0>;
				qcom,prio-wr = <0x0>;
				qom,buswidth = <0x8>;
			};

			bimc-snoc-mas {
				cell-id = <0x2720>;
				label = "bimc_snoc_mas";
				qcom,ap-owned;
				qcom,bus-dev = <0x35>;
				qcom,connections = <0x36>;
				qom,buswidth = <0x8>;
				linux,phandle = <0x33>;
				phandle = <0x33>;
			};

			snoc-bimc-0-slv {
				cell-id = <0x2729>;
				label = "snoc_bimc_0_slv";
				qcom,connections = <0x32>;
				qcom,bus-dev = <0x35>;
				qcom,slv-rpm-id = <0x18>;
				qom,buswidth = <0x8>;
				linux,phandle = <0x2c>;
				phandle = <0x2c>;
			};

			snoc_bimc_1_slv {
				cell-id = <0x272a>;
				label = "snoc_bimc_1_slv";
				qcom,connections = <0x32>;
				qcom,ap-owned;
				qcom,bus-dev = <0x35>;
				qom,buswidth = <0x8>;
				linux,phandle = <0x2d>;
				phandle = <0x2d>;
			};

			snoc_bimc_2_slv {
				cell-id = <0x273e>;
				label = "snoc_bimc_2_slv";
				qcom,connections = <0x32>;
				qcom,ap-owned;
				qcom,bus-dev = <0x35>;
				qom,buswidth = <0x8>;
				linux,phandle = <0x2e>;
				phandle = <0x2e>;
			};

			slv-ebi-ch0 {
				cell-id = <0x200>;
				label = "slv-ebi-ch0";
				qcom,bus-dev = <0x35>;
				qcom,slv-rpm-id = <0x0>;
				qom,buswidth = <0x8>;
				linux,phandle = <0x32>;
				phandle = <0x32>;
			};

			slv-apps-l2 {
				cell-id = <0x202>;
				label = "slv-apps-l2";
				qcom,bus-dev = <0x35>;
				qom,buswidth = <0x8>;
				linux,phandle = <0x34>;
				phandle = <0x34>;
			};

			snoc-pnoc-slv {
				cell-id = <0x273a>;
				label = "snoc-pnoc-slv";
				qcom,connections = <0x37>;
				qcom,bus-dev = <0x38>;
				qcom,buswidth = <0x8>;
				linux,phandle = <0x31>;
				phandle = <0x31>;
			};

			pnoc-int-0 {
				cell-id = <0x271c>;
				label = "pnoc-int-0";
				qcom,connections = <0x39 0x3a 0x3b 0x3c 0x3d 0x3e 0x3f 0x40>;
				qcom,bus-dev = <0x38>;
				qom,buswidth = <0x8>;
				linux,phandle = <0x37>;
				phandle = <0x37>;
			};

			pnoc-int-1 {
				cell-id = <0x271d>;
				label = "pnoc-int-1";
				qcom,connections = <0x39>;
				qcom,bus-dev = <0x38>;
				qom,buswidth = <0x8>;
				linux,phandle = <0x60>;
				phandle = <0x60>;
			};

			pnoc-m-0 {
				cell-id = <0x271e>;
				label = "pnoc-m-0";
				qcom,connections = <0x37>;
				qcom,bus-dev = <0x38>;
				qom,buswidth = <0x8>;
				linux,phandle = <0x5f>;
				phandle = <0x5f>;
			};

			pnoc-m-1 {
				cell-id = <0x271f>;
				label = "pnoc-m-1";
				qcom,connections = <0x39>;
				qcom,bus-dev = <0x38>;
				qom,buswidth = <0x8>;
				linux,phandle = <0x5e>;
				phandle = <0x5e>;
			};

			pnoc-s-0 {
				cell-id = <0x2722>;
				label = "pnoc-s-0";
				qcom,connections = <0x41 0x42 0x43 0x44 0x45>;
				qcom,bus-dev = <0x38>;
				qom,buswidth = <0x4>;
				linux,phandle = <0x3a>;
				phandle = <0x3a>;
			};

			pnoc-s-1 {
				cell-id = <0x2723>;
				label = "pnoc-s-1";
				qcom,connections = <0x46 0x47 0x48 0x49 0x4a>;
				qcom,bus-dev = <0x38>;
				qom,buswidth = <0x4>;
				linux,phandle = <0x3b>;
				phandle = <0x3b>;
			};

			pnoc-s-2 {
				cell-id = <0x2724>;
				label = "pnoc-s-2";
				qcom,connections = <0x4b 0x4c 0x4d 0x4e 0x4f>;
				qcom,bus-dev = <0x38>;
				qom,buswidth = <0x4>;
				linux,phandle = <0x3c>;
				phandle = <0x3c>;
			};

			pnoc-s-3 {
				cell-id = <0x2725>;
				label = "pnoc-s-3";
				qcom,connections = <0x50 0x51 0x52 0x53 0x54>;
				qcom,bus-dev = <0x38>;
				qom,buswidth = <0x4>;
				linux,phandle = <0x3d>;
				phandle = <0x3d>;
			};

			pnoc-s-4 {
				cell-id = <0x2726>;
				label = "pnoc-s-4";
				qcom,connections = <0x55 0x56 0x57>;
				qcom,bus-dev = <0x38>;
				linux,phandle = <0x3e>;
				phandle = <0x3e>;
			};

			pnoc-s-8 {
				cell-id = <0x2727>;
				label = "pnoc-s-8";
				qcom,connections = <0x58 0x59 0x5a>;
				qcom,bus-dev = <0x38>;
				qom,buswidth = <0x4>;
				linux,phandle = <0x3f>;
				phandle = <0x3f>;
			};

			pnoc-s-9 {
				cell-id = <0x2728>;
				label = "pnoc-s-9";
				qcom,connections = <0x5b 0x5c 0x5d>;
				qcom,bus-dev = <0x38>;
				qom,buswidth = <0x4>;
				linux,phandle = <0x40>;
				phandle = <0x40>;
			};

			slv-imem-cfg {
				cell-id = <0x273>;
				label = "slv-imem-cfg";
				qcom,bus-dev = <0x38>;
				qcom,buswidth = <0x4>;
				linux,phandle = <0x46>;
				phandle = <0x46>;
			};

			slv-crypto-0-cfg {
				cell-id = <0x271>;
				label = "slv-crypto-0-cfg";
				qcom,bus-dev = <0x38>;
				qcom,buswidth = <0x4>;
				linux,phandle = <0x47>;
				phandle = <0x47>;
			};

			slv-msg-ram {
				cell-id = <0x217>;
				label = "slv-msg-ram";
				qcom,bus-dev = <0x38>;
				qcom,buswidth = <0x4>;
				linux,phandle = <0x48>;
				phandle = <0x48>;
			};

			slv-pdm {
				cell-id = <0x241>;
				label = "slv-pdm";
				qcom,bus-dev = <0x38>;
				qcom,buswidth = <0x4>;
				linux,phandle = <0x49>;
				phandle = <0x49>;
			};

			slv-prng {
				cell-id = <0x26a>;
				label = "slv-prng";
				qcom,bus-dev = <0x38>;
				qcom,buswidth = <0x4>;
				linux,phandle = <0x4a>;
				phandle = <0x4a>;
			};

			slv-clk-ctl {
				cell-id = <0x26c>;
				label = "slv-clk-ctl";
				qcom,bus-dev = <0x38>;
				qcom,buswidth = <0x4>;
				linux,phandle = <0x41>;
				phandle = <0x41>;
			};

			slv-mss {
				cell-id = <0x26c>;
				label = "slv-mss";
				qcom,bus-dev = <0x38>;
				qcom,buswidth = <0x4>;
				linux,phandle = <0x45>;
				phandle = <0x45>;
			};

			slv-tlmm {
				cell-id = <0x270>;
				label = "slv-tlmm";
				qcom,bus-dev = <0x38>;
				qcom,buswidth = <0x4>;
				linux,phandle = <0x42>;
				phandle = <0x42>;
			};

			slv-tcsr {
				cell-id = <0x243>;
				label = "slv-tcsr";
				qcom,bus-dev = <0x38>;
				qcom,buswidth = <0x4>;
				linux,phandle = <0x43>;
				phandle = <0x43>;
			};

			slv-security {
				cell-id = <0x26e>;
				label = "slv-security";
				qcom,bus-dev = <0x38>;
				qcom,buswidth = <0x4>;
				linux,phandle = <0x44>;
				phandle = <0x44>;
			};

			slv-spdm {
				cell-id = <0x215>;
				label = "slv-spdm";
				qcom,bus-dev = <0x38>;
				qcom,buswidth = <0x4>;
				linux,phandle = <0x4b>;
				phandle = <0x4b>;
			};

			slv-pnoc-cfg {
				cell-id = <0x281>;
				label = "slv-pnoc-cfg";
				qcom,bus-dev = <0x38>;
				qcom,buswidth = <0x4>;
				linux,phandle = <0x4e>;
				phandle = <0x4e>;
			};

			slv-pmic-arb {
				cell-id = <0x278>;
				label = "slv-pmic-arb";
				qcom,bus-dev = <0x38>;
				qcom,buswidth = <0x4>;
				linux,phandle = <0x4f>;
				phandle = <0x4f>;
			};

			slv-bimc-cfg {
				cell-id = <0x275>;
				label = "slv-bimc-cfg";
				qcom,bus-dev = <0x38>;
				qcom,buswidth = <0x4>;
				linux,phandle = <0x4d>;
				phandle = <0x4d>;
			};

			slv-boot-rom {
				cell-id = <0x276>;
				label = "slv-boot-rom";
				qcom,bus-dev = <0x38>;
				qcom,buswidth = <0x4>;
				linux,phandle = <0x4c>;
				phandle = <0x4c>;
			};

			slv-mpm {
				cell-id = <0x218>;
				label = "slv-mpm";
				qcom,bus-dev = <0x38>;
				qcom,buswidth = <0x4>;
				linux,phandle = <0x50>;
				phandle = <0x50>;
			};

			slv-qdss-cfg {
				cell-id = <0x27b>;
				label = "slv-qdss-cfg";
				qcom,bus-dev = <0x38>;
				qcom,buswidth = <0x4>;
				linux,phandle = <0x53>;
				phandle = <0x53>;
			};

			slv-rbcpr-cfg {
				cell-id = <0x27c>;
				label = "slv-rbcpr-cfg";
				qcom,bus-dev = <0x38>;
				qcom,buswidth = <0x4>;
				linux,phandle = <0x52>;
				phandle = <0x52>;
			};

			slv-snoc-cfg {
				cell-id = <0x287>;
				label = "slv-snoc-cfg";
				qcom,bus-dev = <0x38>;
				qcom,buswidth = <0x4>;
				linux,phandle = <0x51>;
				phandle = <0x51>;
			};

			slv-dehr-cfg {
				cell-id = <0x27a>;
				label = "slv-dehr-cfg";
				qcom,bus-dev = <0x38>;
				qcom,buswidth = <0x4>;
				linux,phandle = <0x54>;
				phandle = <0x54>;
			};

			slv-venus-cfg {
				cell-id = <0x254>;
				label = "slv-venus-cfg";
				qcom,bus-dev = <0x38>;
				qcom,buswidth = <0x4>;
				linux,phandle = <0x55>;
				phandle = <0x55>;
			};

			slv-display-cfg {
				cell-id = <0x24e>;
				label = "slv-display-cfg";
				qcom,bus-dev = <0x38>;
				qcom,buswidth = <0x4>;
				linux,phandle = <0x57>;
				phandle = <0x57>;
			};

			slv-camera-cfg {
				cell-id = <0x24d>;
				label = "slv-camer-cfg";
				qcom,bus-dev = <0x38>;
				qcom,buswidth = <0x4>;
				linux,phandle = <0x56>;
				phandle = <0x56>;
			};

			slv-usb-hs {
				cell-id = <0x266>;
				label = "slv-usb-hs";
				qcom,bus-dev = <0x38>;
				qcom,buswidth = <0x4>;
				linux,phandle = <0x58>;
				phandle = <0x58>;
			};

			slv-sdcc-1 {
				cell-id = <0x25e>;
				label = "slv-sdcc-1";
				qcom,bus-dev = <0x38>;
				qcom,buswidth = <0x4>;
				linux,phandle = <0x59>;
				phandle = <0x59>;
			};

			slv-blsp-1 {
				cell-id = <0x265>;
				label = "slv-blsp-1";
				qcom,bus-dev = <0x38>;
				qcom,buswidth = <0x4>;
				linux,phandle = <0x5a>;
				phandle = <0x5a>;
			};

			slv-sdcc-2 {
				cell-id = <0x260>;
				label = "slv-sdcc-2";
				qcom,bus-dev = <0x38>;
				qcom,buswidth = <0x4>;
				linux,phandle = <0x5b>;
				phandle = <0x5b>;
			};

			slv-gfx-cfg {
				cell-id = <0x256>;
				label = "slv-gfx-cfg";
				qcom,bus-dev = <0x38>;
				qcom,buswidth = <0x4>;
				linux,phandle = <0x5d>;
				phandle = <0x5d>;
			};

			slv-audio {
				cell-id = <0x20a>;
				label = "slv-audio";
				qcom,bus-dev = <0x38>;
				qcom,buswidth = <0x4>;
				linux,phandle = <0x5c>;
				phandle = <0x5c>;
			};

			mas-blsp_1 {
				cell-id = <0x56>;
				label = "mas-blsp-1";
				qcom,connections = <0x5e>;
				qcom,bus-dev = <0x38>;
				qcom,buswidth = <0x4>;
			};

			mas-spdm {
				cell-id = <0x24>;
				label = "mas-spdm";
				qcom,connections = <0x5f>;
				qcom,bus-dev = <0x38>;
				qcom,buswidth = <0x4>;
			};

			mas-dehr {
				cell-id = <0x4b>;
				label = "mas-dehr";
				qcom,connections = <0x5f>;
				qcom,bus-dev = <0x38>;
				qcom,buswidth = <0x4>;
			};

			mas-audio {
				cell-id = <0xf>;
				label = "mas-audio";
				qcom,connections = <0x5f>;
				qcom,bus-dev = <0x38>;
				qcom,buswidth = <0x4>;
			};

			mas-usb-hs {
				cell-id = <0x57>;
				label = "mas-usb-hs";
				qcom,connections = <0x5e>;
				qcom,bus-dev = <0x38>;
				qcom,buswidth = <0x4>;
			};

			mas-pnoc-crypto-0 {
				cell-id = <0x37>;
				label = "mas-pnoc-crypto-0";
				qcom,connections = <0x60>;
				qcom,bus-dev = <0x38>;
				qcom,buswidth = <0x8>;
			};

			mas-pnoc-sdcc-1 {
				cell-id = <0x4e>;
				label = "mas-pnoc-sdcc-1";
				qcom,qport = <0x7>;
				qcom,ap-owned;
				qcom,connections = <0x60>;
				qcom,bus-dev = <0x38>;
				qcom,buswidth = <0x8>;
				qcom,qos-mode = "fixed";
				qcom,prio1 = <0x1>;
				qcom,prio0 = <0x1>;
			};

			mas-pnoc-sdcc-2 {
				cell-id = <0x51>;
				label = "mas-pnoc-sdcc-2";
				qcom,qport = <0x8>;
				qcom,ap-owned;
				qcom,connections = <0x60>;
				qcom,bus-dev = <0x38>;
				qcom,buswidth = <0x8>;
				qcom,qos-mode = "fixed";
				qcom,prio1 = <0x1>;
				qcom,prio0 = <0x1>;
			};

			pnoc-snoc-mas {
				cell-id = <0x271a>;
				label = "pnoc-snoc-mas";
				qcom,connections = <0x61>;
				qcom,bus-dev = <0x38>;
				qcom,mas-rpm-id = <0x1d>;
				qcom,buswidth = <0x8>;
				linux,phandle = <0x39>;
				phandle = <0x39>;
			};
		};

		qcom,iommu-domains {
			compatible = "qcom,iommu-domains";

			qcom,iommu-domain1 {
				label = "venus_ns";
				qcom,iommu-contexts = <0x62>;
				qcom,virtual-addr-pool = <0x5dc00000 0x7f000000 0xdcc00000 0x1000000>;
				linux,phandle = <0x8b>;
				phandle = <0x8b>;
			};

			qcom,iommu-domain2 {
				label = "venus_sec_bitstream";
				qcom,iommu-contexts = <0x63>;
				qcom,virtual-addr-pool = <0x4b000000 0x12c00000>;
				qcom,secure-domain;
				linux,phandle = <0x8c>;
				phandle = <0x8c>;
			};

			qcom,iommu-domain3 {
				label = "venus_sec_pixel";
				qcom,iommu-contexts = <0x64>;
				qcom,virtual-addr-pool = <0x25800000 0x25800000>;
				qcom,secure-domain;
				linux,phandle = <0x8d>;
				phandle = <0x8d>;
			};

			qcom,iommu-domain4 {
				label = "venus_sec_non_pixel";
				qcom,iommu-contexts = <0x65>;
				qcom,virtual-addr-pool = <0x1000000 0x24800000>;
				qcom,secure-domain;
				linux,phandle = <0x8e>;
				phandle = <0x8e>;
			};
		};

		interrupt-controller@b000000 {
			compatible = "qcom,msm-qgic2";
			interrupt-controller;
			#interrupt-cells = <0x3>;
			reg = <0xb000000 0x1000 0xb002000 0x1000>;
			linux,phandle = <0x1>;
			phandle = <0x1>;
		};

		gpio@1000000 {
			compatible = "qcom,msm-gpio";
			gpio-controller;
			#gpio-cells = <0x2>;
			interrupt-controller;
			#interrupt-cells = <0x2>;
			reg = <0x1000000 0x300000>;
			ngpio = <0x7a>;
			interrupts = <0x0 0xd0 0x0>;
			qcom,direct-connect-irqs = <0x1d>;
		};

		clock-controller@b088000 {
			compatible = "qcom,arm-cortex-acc";
			reg = <0xb088000 0x1000>;
			linux,phandle = <0x2>;
			phandle = <0x2>;
		};

		clock-controller@b098000 {
			compatible = "qcom,arm-cortex-acc";
			reg = <0xb098000 0x1000>;
			linux,phandle = <0x3>;
			phandle = <0x3>;
		};

		clock-controller@b0a8000 {
			compatible = "qcom,arm-cortex-acc";
			reg = <0xb0a8000 0x1000>;
			linux,phandle = <0x4>;
			phandle = <0x4>;
		};

		clock-controller@b0b8000 {
			compatible = "qcom,arm-cortex-acc";
			reg = <0xb0b8000 0x1000>;
			linux,phandle = <0x5>;
			phandle = <0x5>;
		};

		clock-controller@b188000 {
			compatible = "qcom,arm-cortex-acc";
			reg = <0xb188000 0x1000>;
			linux,phandle = <0x6>;
			phandle = <0x6>;
		};

		clock-controller@b198000 {
			compatible = "qcom,arm-cortex-acc";
			reg = <0xb198000 0x1000>;
			linux,phandle = <0x7>;
			phandle = <0x7>;
		};

		clock-controller@b1a8000 {
			compatible = "qcom,arm-cortex-acc";
			reg = <0xb1a8000 0x1000>;
			linux,phandle = <0x8>;
			phandle = <0x8>;
		};

		clock-controller@b1b8000 {
			compatible = "qcom,arm-cortex-acc";
			reg = <0xb1b8000 0x1000>;
			linux,phandle = <0x9>;
			phandle = <0x9>;
		};

		timer {
			compatible = "arm,armv7-timer";
			interrupts = <0x1 0x2 0xf08 0x1 0x3 0xf08 0x1 0x4 0xf08 0x1 0x1 0xf08>;
			clock-frequency = <0x124f800>;
		};

		timer@b120000 {
			#address-cells = <0x1>;
			#size-cells = <0x1>;
			ranges;
			compatible = "arm,armv7-timer-mem";
			reg = <0xb120000 0x1000>;
			clock-frequency = <0x124f800>;

			frame@b121000 {
				frame-number = <0x0>;
				interrupts = <0x0 0x8 0x4 0x0 0x7 0x4>;
				reg = <0xb121000 0x1000 0xb122000 0x1000>;
			};

			frame@b123000 {
				frame-number = <0x1>;
				interrupts = <0x0 0x9 0x4>;
				reg = <0xb123000 0x1000>;
				status = "disabled";
			};

			frame@b124000 {
				frame-number = <0x2>;
				interrupts = <0x0 0xa 0x4>;
				reg = <0xb124000 0x1000>;
				status = "disabled";
			};

			frame@b125000 {
				frame-number = <0x3>;
				interrupts = <0x0 0xb 0x4>;
				reg = <0xb125000 0x1000>;
				status = "disabled";
			};

			frame@b126000 {
				frame-number = <0x4>;
				interrupts = <0x0 0xc 0x4>;
				reg = <0xb126000 0x1000>;
				status = "disabled";
			};

			frame@b127000 {
				frame-number = <0x5>;
				interrupts = <0x0 0xd 0x4>;
				reg = <0xb127000 0x1000>;
				status = "disabled";
			};

			frame@b128000 {
				frame-number = <0x6>;
				interrupts = <0x0 0xe 0x4>;
				reg = <0xb128000 0x1000>;
				status = "disabled";
			};
		};

		qcom,sps {
			compatible = "qcom,msm_sps_4k";
			qcom,device-type = <0x3>;
			qcom,pipe-attr-ee;
		};

		qcom,ipc-spinlock@1905000 {
			compatible = "qcom,ipc-spinlock-sfpb";
			reg = <0x1905000 0x8000>;
			qcom,num-locks = <0x8>;
		};

		qcom,wdt@b017000 {
			compatible = "qcom,msm-watchdog";
			reg = <0xb017000 0x1000>;
			interrupts = <0x0 0x3 0x0 0x0 0x4 0x0>;
			qcom,bark-time = <0x2af8>;
			qcom,pet-time = <0x2710>;
			qcom,ipi-ping;
		};

		qcom,msm-rtb {
			compatible = "qcom,msm-rtb";
			qcom,rtb-size = <0x100000>;
		};

		qcom,smem@86300000 {
			compatible = "qcom,smem";
			reg = <0x86300000 0x100000 0xb111008 0x4 0x60000 0x8000 0x193d000 0x8>;
			reg-names = "smem", "irq-reg-base", "aux-mem1", "smem_targ_info_reg";
			qcom,mpu-enabled;

			qcom,smd-modem {
				compatible = "qcom,smd";
				qcom,smd-edge = <0x0>;
				qcom,smd-irq-offset = <0x0>;
				qcom,smd-irq-bitmask = <0x1000>;
				interrupts = <0x0 0x19 0x1>;
				label = "modem";
			};

			qcom,smsm-modem {
				compatible = "qcom,smsm";
				qcom,smsm-edge = <0x0>;
				qcom,smsm-irq-offset = <0x0>;
				qcom,smsm-irq-bitmask = <0x2000>;
				interrupts = <0x0 0x1a 0x1>;
			};

			qcom,smd-wcnss {
				compatible = "qcom,smd";
				qcom,smd-edge = <0x6>;
				qcom,smd-irq-offset = <0x0>;
				qcom,smd-irq-bitmask = <0x20000>;
				interrupts = <0x0 0x8e 0x1>;
				label = "wcnss";
			};

			qcom,smsm-wcnss {
				compatible = "qcom,smsm";
				qcom,smsm-edge = <0x6>;
				qcom,smsm-irq-offset = <0x0>;
				qcom,smsm-irq-bitmask = <0x80000>;
				interrupts = <0x0 0x90 0x1>;
			};

			qcom,smd-rpm {
				compatible = "qcom,smd";
				qcom,smd-edge = <0xf>;
				qcom,smd-irq-offset = <0x0>;
				qcom,smd-irq-bitmask = <0x1>;
				interrupts = <0x0 0xa8 0x1>;
				label = "rpm";
				qcom,irq-no-suspend;
				qcom,not-loadable;
			};
		};

		qcom,rpm-smd {
			compatible = "qcom,rpm-smd";
			rpm-channel-name = "rpm_requests";
			rpm-channel-type = <0xf>;
			rpm-standalone;
		};

		qcom,bam_dmux@4044000 {
			compatible = "qcom,bam_dmux";
			reg = <0x4044000 0x19000>;
			interrupts = <0x0 0x1d 0x1>;
			qcom,rx-ring-size = <0x20>;
		};

		qcom,smdtty {
			compatible = "qcom,smdtty";

			qcom,smdtty-apps-fm {
				qcom,smdtty-remote = "wcnss";
				qcom,smdtty-port-name = "APPS_FM";
			};

			smdtty-apps-riva-bt-acl {
				qcom,smdtty-remote = "wcnss";
				qcom,smdtty-port-name = "APPS_RIVA_BT_ACL";
			};

			qcom,smdtty-apps-riva-bt-cmd {
				qcom,smdtty-remote = "wcnss";
				qcom,smdtty-port-name = "APPS_RIVA_BT_CMD";
			};

			smdtty-apps-riva-ant-cmd {
				qcom,smdtty-remote = "wcnss";
				qcom,smdtty-port-name = "APPS_RIVA_ANT_CMD";
			};

			smdtty-apps-riva-ant-data {
				qcom,smdtty-remote = "wcnss";
				qcom,smdtty-port-name = "APPS_RIVA_ANT_DATA";
			};

			qcom,smdtty-data1 {
				qcom,smdtty-remote = "modem";
				qcom,smdtty-port-name = "DATA1";
			};

			qcom,smdtty-data4 {
				qcom,smdtty-remote = "modem";
				qcom,smdtty-port-name = "DATA4";
			};

			qcom,smdtty-data11 {
				qcom,smdtty-remote = "modem";
				qcom,smdtty-port-name = "DATA11";
			};

			qcom,smdtty-data21 {
				qcom,smdtty-remote = "modem";
				qcom,smdtty-port-name = "DATA21";
			};

			smdtty-loopback {
				qcom,smdtty-remote = "modem";
				qcom,smdtty-port-name = "LOOPBACK";
				qcom,smdtty-dev-name = "LOOPBACK_TTY";
			};
		};

		qcom,smdpkt {
			compatible = "qcom,smdpkt";

			qcom,smdpkt-data5-cntl {
				qcom,smdpkt-remote = "modem";
				qcom,smdpkt-port-name = "DATA5_CNTL";
				qcom,smdpkt-dev-name = "smdcntl0";
			};

			qcom,smdpkt-data6-cntl {
				qcom,smdpkt-remote = "modem";
				qcom,smdpkt-port-name = "DATA6_CNTL";
				qcom,smdpkt-dev-name = "smdcntl1";
			};

			qcom,smdpkt-data7-cntl {
				qcom,smdpkt-remote = "modem";
				qcom,smdpkt-port-name = "DATA7_CNTL";
				qcom,smdpkt-dev-name = "smdcntl2";
			};

			qcom,smdpkt-data8-cntl {
				qcom,smdpkt-remote = "modem";
				qcom,smdpkt-port-name = "DATA8_CNTL";
				qcom,smdpkt-dev-name = "smdcntl3";
			};

			qcom,smdpkt-data9-cntl {
				qcom,smdpkt-remote = "modem";
				qcom,smdpkt-port-name = "DATA9_CNTL";
				qcom,smdpkt-dev-name = "smdcntl4";
			};

			qcom,smdpkt-data12-cntl {
				qcom,smdpkt-remote = "modem";
				qcom,smdpkt-port-name = "DATA12_CNTL";
				qcom,smdpkt-dev-name = "smdcntl5";
			};

			qcom,smdpkt-data13-cntl {
				qcom,smdpkt-remote = "modem";
				qcom,smdpkt-port-name = "DATA13_CNTL";
				qcom,smdpkt-dev-name = "smdcntl6";
			};

			qcom,smdpkt-data14-cntl {
				qcom,smdpkt-remote = "modem";
				qcom,smdpkt-port-name = "DATA14_CNTL";
				qcom,smdpkt-dev-name = "smdcntl7";
			};

			qcom,smdpkt-data15-cntl {
				qcom,smdpkt-remote = "modem";
				qcom,smdpkt-port-name = "DATA15_CNTL";
				qcom,smdpkt-dev-name = "smdcntl9";
			};

			qcom,smdpkt-data16-cntl {
				qcom,smdpkt-remote = "modem";
				qcom,smdpkt-port-name = "DATA16_CNTL";
				qcom,smdpkt-dev-name = "smdcntl10";
			};

			qcom,smdpkt-data17-cntl {
				qcom,smdpkt-remote = "modem";
				qcom,smdpkt-port-name = "DATA17_CNTL";
				qcom,smdpkt-dev-name = "smdcntl11";
			};

			qcom,smdpkt-data22 {
				qcom,smdpkt-remote = "modem";
				qcom,smdpkt-port-name = "DATA22";
				qcom,smdpkt-dev-name = "smd22";
			};

			qcom,smdpkt-data23-cntl {
				qcom,smdpkt-remote = "modem";
				qcom,smdpkt-port-name = "DATA23_CNTL";
				qcom,smdpkt-dev-name = "smdcnt_rev0";
			};

			qcom,smdpkt-data24-cntl {
				qcom,smdpkt-remote = "modem";
				qcom,smdpkt-port-name = "DATA24_CNTL";
				qcom,smdpkt-dev-name = "smdcnt_rev1";
			};

			qcom,smdpkt-data25-cntl {
				qcom,smdpkt-remote = "modem";
				qcom,smdpkt-port-name = "DATA25_CNTL";
				qcom,smdpkt-dev-name = "smdcnt_rev2";
			};

			qcom,smdpkt-data26-cntl {
				qcom,smdpkt-remote = "modem";
				qcom,smdpkt-port-name = "DATA26_CNTL";
				qcom,smdpkt-dev-name = "smdcnt_rev3";
			};

			qcom,smdpkt-data27-cntl {
				qcom,smdpkt-remote = "modem";
				qcom,smdpkt-port-name = "DATA27_CNTL";
				qcom,smdpkt-dev-name = "smdcnt_rev4";
			};

			qcom,smdpkt-data28-cntl {
				qcom,smdpkt-remote = "modem";
				qcom,smdpkt-port-name = "DATA28_CNTL";
				qcom,smdpkt-dev-name = "smdcnt_rev5";
			};

			qcom,smdpkt-data29-cntl {
				qcom,smdpkt-remote = "modem";
				qcom,smdpkt-port-name = "DATA29_CNTL";
				qcom,smdpkt-dev-name = "smdcnt_rev6";
			};

			qcom,smdpkt-data30-cntl {
				qcom,smdpkt-remote = "modem";
				qcom,smdpkt-port-name = "DATA30_CNTL";
				qcom,smdpkt-dev-name = "smdcnt_rev7";
			};

			qcom,smdpkt-data31-cntl {
				qcom,smdpkt-remote = "modem";
				qcom,smdpkt-port-name = "DATA31_CNTL";
				qcom,smdpkt-dev-name = "smdcnt_rev8";
			};

			qcom,smdpkt-data40-cntl {
				qcom,smdpkt-remote = "modem";
				qcom,smdpkt-port-name = "DATA40_CNTL";
				qcom,smdpkt-dev-name = "smdcntl8";
			};

			qcom,smdpkt-apr-apps2 {
				qcom,smdpkt-remote = "modem";
				qcom,smdpkt-port-name = "apr_apps2";
				qcom,smdpkt-dev-name = "apr_apps2";
			};

			qcom,smdpkt-loopback {
				qcom,smdpkt-remote = "modem";
				qcom,smdpkt-port-name = "LOOPBACK";
				qcom,smdpkt-dev-name = "smd_pkt_loopback";
			};
		};

		tsens@4a8000 {
			compatible = "qcom,msm8939-tsens";
			reg = <0x4a8000 0x2000 0x5c000 0x1000>;
			reg-names = "tsens_physical", "tsens_eeprom_physical";
			interrupts = <0x0 0xb8 0x0>;
			qcom,sensors = <0x9>;
			qcom,slope = <0xc80 0xc80 0xc80 0xc80 0xc80 0xc80 0xc80 0xc80 0xc80>;
			qcom,sensor-id = <0x0 0x1 0x2 0x3 0x5 0x6 0x7 0x8 0x9>;
		};

		qcom,rpmcc@1874000 {
			compatible = "qcom,rpmcc-8936";
			reg = <0x1874000 0x4>;
			reg-names = "cc_base";
			#clock-cells = <0x1>;
			linux,phandle = <0x17>;
			phandle = <0x17>;
		};

		qcom,gcc@1800000 {
			compatible = "qcom,gcc-8936";
			reg = <0x1800000 0x80000>;
			reg-names = "cc_base";
			vdd_dig-supply = <0x66>;
			clocks = <0x17 0x6ac2a778 0x17 0x2fdd2c7c>;
			clock-names = "xo", "xo_a";
			#clock-cells = <0x1>;
			linux,phandle = <0x1c>;
			phandle = <0x1c>;
		};

		qcom,cc-debug@1874000 {
			compatible = "qcom,cc-debug-8936";
			reg = <0x1874000 0x4>;
			reg-names = "cc_base";
			clocks = <0x17 0x25cd1f3a>;
			clock-names = "rpm_debug_mux";
			#clock-cells = <0x1>;
		};

		tz-log@8600720 {
			compatible = "qcom,tz-log";
			reg = <0x8600720 0x1000>;
			status = "disabled";
		};

		qrng@22000 {
			compatible = "qcom,msm-rng";
			reg = <0x22000 0x200>;
			qcom,msm-rng-iface-clk;
			qcom,msm-bus,name = "msm-rng-noc";
			qcom,msm-bus,num-cases = <0x2>;
			qcom,msm-bus,num-paths = <0x1>;
			qcom,msm-bus,vectors-KBps = <0x1 0x26a 0x0 0x0 0x1 0x26a 0x0 0x320>;
			clocks = <0x1c 0x397e7eaa>;
			clock-names = "iface_clk";
			status = "disabled";
		};

		qcom,msm-adsp-loader {
			compatible = "qcom,adsp-loader";
			qcom,adsp-state = <0x0>;
			qcom,proc-img-to-load = "modem";
		};

		qcrypto@720000 {
			compatible = "qcom,qcrypto";
			reg = <0x720000 0x20000 0x704000 0x20000>;
			reg-names = "crypto-base", "crypto-bam-base";
			interrupts = <0x0 0xcf 0x0>;
			qcom,bam-pipe-pair = <0x2>;
			qcom,ce-hw-instance = <0x0>;
			qcom,ce-device = <0x0>;
			qcom,ce-hw-shared;
			qcom,msm-bus,name = "qcrypto-noc";
			qcom,msm-bus,num-cases = <0x2>;
			qcom,msm-bus,num-paths = <0x1>;
			qcom,msm-bus,vectors-KBps = <0x37 0x200 0x0 0x0 0x37 0x200 0x3c0f00 0x60180>;
			clocks = <0x1c 0x37a21414 0x1c 0xd390d2 0x1c 0x94de4919 0x1c 0xd4415c9b>;
			clock-names = "core_clk_src", "core_clk", "iface_clk", "bus_clk";
			status = "disabled";
		};

		qcedev@720000 {
			compatible = "qcom,qcedev";
			reg = <0x720000 0x20000 0x704000 0x20000>;
			reg-names = "crypto-base", "crypto-bam-base";
			interrupts = <0x0 0xcf 0x0>;
			qcom,bam-pipe-pair = <0x1>;
			qcom,ce-hw-instance = <0x0>;
			qcom,ce-device = <0x0>;
			qcom,ce-hw-shared;
			qcom,msm-bus,name = "qcedev-noc";
			qcom,msm-bus,num-cases = <0x2>;
			qcom,msm-bus,num-paths = <0x1>;
			qcom,msm-bus,vectors-KBps = <0x37 0x200 0x0 0x0 0x37 0x200 0x3c0f00 0x60180>;
			clocks = <0x1c 0x37a21414 0x1c 0xd390d2 0x1c 0x94de4919 0x1c 0xd4415c9b>;
			clock-names = "core_clk_src", "core_clk", "iface_clk", "bus_clk";
			status = "disabled";
		};

		qseecom@8e700000 {
			compatible = "qcom,qseecom";
			reg = <0x8e700000 0x300000>;
			reg-names = "secapp-region";
			qcom,disk-encrypt-pipe-pair = <0x2>;
			qcom,hlos-ce-hw-instance = <0x0>;
			qcom,qsee-ce-hw-instance = <0x0>;
			qcom,msm-bus,name = "qseecom-noc";
			qcom,msm-bus,num-cases = <0x4>;
			qcom,msm-bus,num-paths = <0x1>;
			qcom,support-bus-scaling;
			qcom,msm-bus,vectors-KBps = <0x37 0x200 0x0 0x0 0x37 0x200 0x0 0x0 0x37 0x200 0x1d4c0 0x124f80 0x37 0x200 0x60180 0x3c0f00>;
			clocks = <0x1c 0x37a21414 0x1c 0xd390d2 0x1c 0x94de4919 0x1c 0xd4415c9b>;
			clock-names = "core_clk_src", "core_clk", "iface_clk", "bus_clk";
			status = "disabled";
		};

		usb@78d9000 {
			compatible = "qcom,hsusb-otg";
			reg = <0x78d9000 0x400>;
			interrupts = <0x0 0x86 0x0 0x0 0x8c 0x0>;
			interrupt-names = "core_irq", "async_irq";
			hsusb_vdd_dig-supply = <0x66>;
			HSUSB_1p8-supply = <0x67>;
			HSUSB_3p3-supply = <0x68>;
			qcom,vdd-voltage-level = <0x1 0x5 0x7>;
			qcom,hsusb-otg-phy-type = <0x2>;
			qcom,hsusb-otg-mode = <0x1>;
			qcom,hsusb-otg-otg-control = <0x1>;
			qcom,hsusb-otg-disable-reset;
			qcom,msm-bus,name = "usb2";
			qcom,msm-bus,num-cases = <0x3>;
			qcom,msm-bus,num-paths = <0x1>;
			qcom,msm-bus,vectors-KBps = <0x57 0x200 0x0 0x0 0x57 0x200 0xea60 0xea600 0x57 0x200 0x1770 0x1770>;
			clocks = <0x1c 0x72ce8032 0x1c 0xa11972e5 0x1c 0x6caa736f 0x17 0x79bca5cc>;
			clock-names = "iface_clk", "core_clk", "sleep_clk", "xo";
		};

		android_usb {
			compatible = "qcom,android-usb";
			qcom,android-usb-swfi-latency = <0x1>;
		};

		serial@78af000 {
			compatible = "qcom,msm-lsuart-v14";
			reg = <0x78af000 0x200>;
			interrupts = <0x0 0x6b 0x0>;
			status = "disabled";
			clocks = <0x1c 0xc7c62f90 0x1c 0x8caa5b4f>;
			clock-names = "core_clk", "iface_clk";
		};

		serial@78b0000 {
			compatible = "qcom,msm-lsuart-v14";
			reg = <0x78b0000 0x200>;
			interrupts = <0x0 0x6c 0x0>;
			status = "ok";
			clocks = <0x1c 0xf8a61c96 0x1c 0x8caa5b4f>;
			clock-names = "core_clk", "iface_clk";
			pinctrl-names = "default";
			pinctrl-0 = <0x69>;
		};

		i2c@78b6000 {
			compatible = "qcom,i2c-msm-v2";
			#address-cells = <0x1>;
			#size-cells = <0x0>;
			reg-names = "qup_phys_addr", "bam_phys_addr";
			reg = <0x78b6000 0x600 0x7884000 0x23000>;
			interrupt-names = "qup_irq", "bam_irq";
			interrupts = <0x0 0x60 0x0 0x0 0xee 0x0>;
			clocks = <0x1c 0x8caa5b4f 0x1c 0x1076f220>;
			clock-names = "iface_clk", "core_clk";
			qcom,clk-freq-out = <0x186a0>;
			qcom,clk-freq-in = <0x124f800>;
			pinctrl-names = "i2c_active", "i2c_sleep";
			pinctrl-0 = <0x6a>;
			pinctrl-1 = <0x6b>;
			qcom,noise-rjct-scl = <0x0>;
			qcom,noise-rjct-sda = <0x0>;
			qcom,bam-pipe-idx-cons = <0x6>;
			qcom,bam-pipe-idx-prod = <0x7>;
			qcom,master-id = <0x56>;

			avago@39 {
				compatible = "avago,apds9930";
				reg = <0x39>;
				pinctrl-names = "apds_default", "apds_sleep";
				pinctrl-0 = <0x6c>;
				pinctrl-1 = <0x6d>;
				interrupt-parent = <0x6e>;
				interrupts = <0x71 0x2002>;
				vdd-supply = <0x6f>;
				vio-supply = <0x70>;
				avago,irq-gpio = <0x6e 0x71 0x2002>;
				avago,ps-threshold = <0x258>;
				avago,ps-hysteresis_threshold = <0x1f4>;
				avago,ps-pulse = <0x8>;
				avago,ps-pgain = <0x0>;
				avago,als-B = <0xdf>;
				avago,als-C = <0x46>;
				avago,als-D = <0x8e>;
				avago,ga-value = <0x30>;
			};

			bosch@18 {
				compatible = "bosch,bma2x2";
				reg = <0x18>;
				pinctrl-names = "bma_default", "bma_sleep";
				pinctrl-0 = <0x71 0x72>;
				pinctrl-1 = <0x73 0x74>;
				interrupt-parent = <0x6e>;
				interrupts = <0x70 0x2002>;
				vdd-supply = <0x6f>;
				vio-supply = <0x70>;
				bosch,init-interval = <0xc8>;
				bosch,place = <0x2>;
				bosch,gpio-int1 = <0x6e 0x70 0x2002>;
				bosch,gpio-int2 = <0x6e 0x72 0x2002>;
			};

			memsic@30 {
				compatible = "memsic,mmc3416x";
				reg = <0x30>;
				vdd-supply = <0x6f>;
				vio-supply = <0x70>;
				memsic,dir = "obverse-x-axis-forward";
				memsic,auto-report;
			};

			mpu6050@68 {
				compatible = "invn,mpu6050";
				reg = <0x68>;
				pinctrl-names = "mpu_default", "mpu_sleep";
				pinctrl-0 = <0x75>;
				pinctrl-1 = <0x76>;
				interrupt-parent = <0x6e>;
				interrupts = <0x73 0x2002>;
				vdd-supply = <0x6f>;
				vlogic-supply = <0x77>;
				invn,gpio-int = <0x6e 0x73 0x2002>;
				invn,place = "Portrait Down Back Side";
			};

			tps65132@3e {
				compatible = "ti,tps65132";
				reg = <0x3e>;
				i2c-pwr-supply = <0x70>;
				pinctrl-names = "default";
				pinctrl-0 = <0x78>;
				status = "disabled";

				regulators {

					pos-boost {
						regulator-name = "tps65132-pos";
						regulator-min-microvolt = <0x588040>;
						regulator-max-microvolt = <0x588040>;
						ti,discharge-enable;
						ti,enable-time = <0x320>;
						ti,current-limit = <0x30d40>;
						ti,en-gpio = <0x6e 0x61 0x0>;
					};

					neg-boost {
						regulator-name = "tps65132-neg";
						regulator-min-microvolt = <0x588040>;
						regulator-max-microvolt = <0x588040>;
						ti,discharge-enable;
						ti,enable-time = <0x320>;
						ti,current-limit = <0x9c40>;
						ti,en-gpio = <0x6e 0x62 0x0>;
					};
				};
			};
		};

		spi@78b7000 {
			compatible = "qcom,spi-qup-v2";
			#address-cells = <0x1>;
			#size-cells = <0x0>;
			reg-names = "spi_physical", "spi_bam_physical";
			reg = <0x78b7000 0x600 0x7884000 0x23000>;
			interrupt-names = "spi_irq", "spi_bam_irq";
			interrupts = <0x0 0x61 0x0 0x0 0xee 0x0>;
			spi-max-frequency = <0x124f800>;
			pinctrl-names = "default", "sleep";
			pinctrl-0 = <0x79 0x7a>;
			pinctrl-1 = <0x7b 0x7c>;
			clocks = <0x1c 0x8caa5b4f 0x1c 0xfb978880>;
			clock-names = "iface_clk", "core_clk";
			qcom,infinite-mode = <0x0>;
			qcom,use-bam;
			qcom,use-pinctrl;
			qcom,ver-reg-exists;
			qcom,bam-consumer-pipe-index = <0x8>;
			qcom,bam-producer-pipe-index = <0x9>;
			qcom,master-id = <0x56>;
		};

		i2c@78b8000 {
			compatible = "qcom,i2c-msm-v2";
			#address-cells = <0x1>;
			#size-cells = <0x0>;
			reg-names = "qup_phys_addr", "bam_phys_addr";
			reg = <0x78b8000 0x1000 0x7884000 0x23000>;
			interrupt-names = "qup_irq", "bam_irq";
			interrupts = <0x0 0x62 0x0 0x0 0xee 0x0>;
			qcom,clk-freq-out = <0x186a0>;
			qcom,clk-freq-in = <0x124f800>;
			clock-names = "iface_clk", "core_clk";
			clocks = <0x1c 0x8caa5b4f 0x1c 0xd7f40f6f>;
			pinctrl-names = "i2c_active", "i2c_sleep";
			pinctrl-0 = <0x7d>;
			pinctrl-1 = <0x7e>;
			qcom,noise-rjct-scl = <0x0>;
			qcom,noise-rjct-sda = <0x0>;
			qcom,bam-pipe-idx-cons = <0xa>;
			qcom,bam-pipe-idx-prod = <0xb>;
			qcom,master-id = <0x56>;

			ncp6335d-regulator@1c {
				compatible = "onnn,ncp6335d-regulator";
				reg = <0x1c>;
				onnn,vsel = <0x0>;
				onnn,slew-ns = <0xd05>;
				onnn,step-size = <0x186a>;
				onnn,min-slew-ns = <0x1a0>;
				onnn,max-slew-ns = <0xd05>;
				regulator-min-microvolt = <0x100590>;
				regulator-max-microvolt = <0x149970>;
				onnn,min-setpoint = <0x927c0>;
				pintrl-names = "default";
				pinctrl-0 = <0x7f>;
				onnn,vsel-gpio = <0x6e 0x6f 0x1>;
				onnn,discharge-enable;
				onnn,restore-reg;
			};

			fan53555-regulator@60 {
				compatible = "fairchild,fan53555-regulator";
				reg = <0x60>;
				fairchild,backup-vsel = <0x1>;
				regulator-min-microvolt = <0x100590>;
				regulator-max-microvolt = <0x149970>;
				regulator-ramp-delay = <0x4e2>;
				pintrl-names = "default";
				pinctrl-0 = <0x7f>;
				fairchild,vsel-gpio = <0x6e 0x6f 0x1>;
				fairchild,restore-reg;
				fairchild,disable-suspend;
			};

			smb1360-chg-fg@14 {
				compatible = "qcom,smb1360-chg-fg";
				reg = <0x14>;
				status = "disabled";
				interrupt-parent = <0x6e>;
				interrupts = <0x3e 0x2>;
				pinctrl-names = "default";
				pinctrl-0 = <0x80>;
				qcom,chg-inhibit-disabled;
				qcom,float-voltage-mv = <0x10fe>;
				qcom,iterm-ma = <0xc8>;
				qcom,otg-batt-curr-limit = <0x3b6>;
				qcom,recharge-thresh-mv = <0x64>;
				qcom,thermal-mitigation = <0x5dc 0x2bc 0x258 0x0>;
				qcom,fg-auto-recharge-soc = <0x63>;
				regulator-name = "smb1360_otg_vreg";
			};
		};

		qcom,spmi@200f000 {
			compatible = "qcom,spmi-pmic-arb";
			reg = <0x200f000 0x1000 0x2400000 0x400000 0x2c00000 0x400000 0x3800000 0x200000 0x200a000 0x2100>;
			reg-names = "core", "chnls", "obsrvr", "intr", "cnfg";
			interrupts = <0x0 0xbe 0x0>;
			qcom,pmic-arb-channel = <0x0>;
			qcom,pmic-arb-ee = <0x0>;
			#interrupt-cells = <0x3>;
			interrupt-controller;
			#address-cells = <0x1>;
			#size-cells = <0x0>;
			cell-index = <0x0>;
			qcom,not-wakeup;
			linux,phandle = <0x86>;
			phandle = <0x86>;

			qcom,pm8916@0 {
				spmi-slave-container;
				reg = <0x0>;
				#address-cells = <0x1>;
				#size-cells = <0x1>;

				qcom,revid@100 {
					compatible = "qcom,qpnp-revid";
					reg = <0x100 0x100>;
					linux,phandle = <0x81>;
					phandle = <0x81>;
				};

				qcom,power-on@800 {
					compatible = "qcom,qpnp-power-on";
					reg = <0x800 0x100>;
					interrupts = <0x0 0x8 0x0 0x0 0x8 0x1>;
					interrupt-names = "kpdpwr", "resin";
					qcom,pon-dbc-delay = <0x3d09>;
					qcom,system-reset;
					qcom,s3-debounce = <0x10>;
					qcom,s3-src = "kpdpwr";

					qcom,pon_1 {
						qcom,pon-type = <0x0>;
						qcom,support-reset = <0x1>;
						qcom,pull-up = <0x1>;
						qcom,s1-timer = <0x2810>;
						qcom,s2-timer = <0x7d0>;
						qcom,s2-type = <0x7>;
						linux,code = <0x74>;
					};

					qcom,pon_2 {
						qcom,pon-type = <0x1>;
						qcom,pull-up = <0x1>;
						linux,code = <0x72>;
					};
				};

				mpps {
					compatible = "qcom,qpnp-pin";
					spmi-dev-container;
					gpio-controller;
					#gpio-cells = <0x2>;
					#address-cells = <0x1>;
					#size-cells = <0x1>;
					label = "pm8916-mpp";

					mpp@a000 {
						reg = <0xa000 0x100>;
						qcom,pin-num = <0x1>;
					};

					mpp@a100 {
						reg = <0xa100 0x100>;
						qcom,pin-num = <0x2>;
					};

					mpp@a200 {
						reg = <0xa200 0x100>;
						qcom,pin-num = <0x3>;
					};

					mpp@a300 {
						reg = <0xa300 0x100>;
						qcom,pin-num = <0x4>;
					};
				};

				gpios {
					compatible = "qcom,qpnp-pin";
					spmi-dev-container;
					gpio-controller;
					#gpio-cells = <0x2>;
					#address-cells = <0x1>;
					#size-cells = <0x1>;
					label = "pm8916-gpio";

					gpio@c000 {
						reg = <0xc000 0x100>;
						qcom,pin-num = <0x1>;
					};

					gpio@c100 {
						reg = <0xc100 0x100>;
						qcom,pin-num = <0x2>;
					};

					gpio@c200 {
						reg = <0xc200 0x100>;
						qcom,pin-num = <0x3>;
					};

					gpio@c300 {
						reg = <0xc300 0x100>;
						qcom,pin-num = <0x4>;
					};
				};

				qcom,pm8916_rtc {
					spmi-dev-container;
					compatible = "qcom,qpnp-rtc";
					#address-cells = <0x1>;
					#size-cells = <0x1>;
					qcom,qpnp-rtc-write = <0x0>;
					qcom,qpnp-rtc-alarm-pwrup = <0x0>;

					qcom,pm8916_rtc_rw@6000 {
						reg = <0x6000 0x100>;
					};

					qcom,pm8916_rtc_alarm@6100 {
						reg = <0x6100 0x100>;
						interrupts = <0x0 0x61 0x1>;
					};
				};

				vadc@3100 {
					compatible = "qcom,qpnp-vadc";
					reg = <0x3100 0x100>;
					#address-cells = <0x1>;
					#size-cells = <0x0>;
					interrupts = <0x0 0x31 0x0>;
					interrupt-names = "eoc-int-en-set";
					qcom,adc-bit-resolution = <0xf>;
					qcom,adc-vdd-reference = <0x708>;
					qcom,vadc-poll-eoc;
					qcom,pmic-revid = <0x81>;
					linux,phandle = <0x82>;
					phandle = <0x82>;

					chan@8 {
						label = "die_temp";
						reg = <0x8>;
						qcom,decimation = <0x0>;
						qcom,pre-div-channel-scaling = <0x0>;
						qcom,calibration-type = "absolute";
						qcom,scale-function = <0x3>;
						qcom,hw-settle-time = <0x0>;
						qcom,fast-avg-setup = <0x0>;
					};

					chan@9 {
						label = "ref_625mv";
						reg = <0x9>;
						qcom,decimation = <0x0>;
						qcom,pre-div-channel-scaling = <0x0>;
						qcom,calibration-type = "absolute";
						qcom,scale-function = <0x0>;
						qcom,hw-settle-time = <0x0>;
						qcom,fast-avg-setup = <0x0>;
					};

					chan@a {
						label = "ref_1250v";
						reg = <0xa>;
						qcom,decimation = <0x0>;
						qcom,pre-div-channel-scaling = <0x0>;
						qcom,calibration-type = "absolute";
						qcom,scale-function = <0x0>;
						qcom,hw-settle-time = <0x0>;
						qcom,fast-avg-setup = <0x0>;
					};

					chan@0 {
						label = "usb_in";
						reg = <0x0>;
						qcom,decimation = <0x0>;
						qcom,pre-div-channel-scaling = <0x7>;
						qcom,calibration-type = "absolute";
						qcom,scale-function = <0x0>;
						qcom,hw-settle-time = <0x0>;
						qcom,fast-avg-setup = <0x0>;
					};

					chan@2 {
						label = "ireg_fb";
						reg = <0x2>;
						qcom,decimation = <0x0>;
						qcom,pre-div-channel-scaling = <0x6>;
						qcom,calibration-type = "absolute";
						qcom,scale-function = <0x0>;
						qcom,hw-settle-time = <0x0>;
						qcom,fast-avg-setup = <0x0>;
					};

					chan@5 {
						label = "vcoin";
						reg = <0x5>;
						qcom,decimation = <0x0>;
						qcom,pre-div-channel-scaling = <0x1>;
						qcom,calibration-type = "absolute";
						qcom,scale-function = <0x0>;
						qcom,hw-settle-time = <0x0>;
						qcom,fast-avg-setup = <0x0>;
					};

					chan@6 {
						label = "vbat_sns";
						reg = <0x6>;
						qcom,decimation = <0x0>;
						qcom,pre-div-channel-scaling = <0x1>;
						qcom,calibration-type = "absolute";
						qcom,scale-function = <0x0>;
						qcom,hw-settle-time = <0x0>;
						qcom,fast-avg-setup = <0x0>;
					};

					chan@7 {
						label = "vph_pwr";
						reg = <0x7>;
						qcom,decimation = <0x0>;
						qcom,pre-div-channel-scaling = <0x1>;
						qcom,calibration-type = "absolute";
						qcom,scale-function = <0x0>;
						qcom,hw-settle-time = <0x0>;
						qcom,fast-avg-setup = <0x0>;
					};

					chan@b {
						label = "chg_temp";
						reg = <0xb>;
						qcom,decimation = <0x0>;
						qcom,pre-div-channel-scaling = <0x0>;
						qcom,calibration-type = "absolute";
						qcom,scale-function = <0x3>;
						qcom,hw-settle-time = <0x0>;
						qcom,fast-avg-setup = <0x0>;
					};

					chan@30 {
						label = "batt_therm";
						reg = <0x30>;
						qcom,decimation = <0x0>;
						qcom,pre-div-channel-scaling = <0x0>;
						qcom,calibration-type = "ratiometric";
						qcom,scale-function = <0x1>;
						qcom,hw-settle-time = <0xb>;
						qcom,fast-avg-setup = <0x0>;
					};

					chan@31 {
						label = "batt_id";
						reg = <0x31>;
						qcom,decimation = <0x0>;
						qcom,pre-div-channel-scaling = <0x0>;
						qcom,calibration-type = "ratiometric";
						qcom,scale-function = <0x0>;
						qcom,hw-settle-time = <0xb>;
						qcom,fast-avg-setup = <0x0>;
					};

					chan@36 {
						label = "pa_therm0";
						reg = <0x36>;
						qcom,decimation = <0x0>;
						qcom,pre-div-channel-scaling = <0x0>;
						qcom,calibration-type = "ratiometric";
						qcom,scale-function = <0x2>;
						qcom,hw-settle-time = <0x2>;
						qcom,fast-avg-setup = <0x0>;
					};
				};

				qcom,temp-alarm@2400 {
					compatible = "qcom,qpnp-temp-alarm";
					reg = <0x2400 0x100>;
					interrupts = <0x0 0x24 0x0>;
					label = "pm8916_tz";
					qcom,channel-num = <0x8>;
					qcom,threshold-set = <0x0>;
					qcom,temp_alarm-vadc = <0x82>;
				};

				vadc@3400 {
					compatible = "qcom,qpnp-adc-tm";
					reg = <0x3400 0x100>;
					#address-cells = <0x1>;
					#size-cells = <0x0>;
					interrupts = <0x0 0x34 0x0 0x0 0x34 0x3 0x0 0x34 0x4>;
					interrupt-names = "eoc-int-en-set", "high-thr-en-set", "low-thr-en-set";
					qcom,adc-bit-resolution = <0xf>;
					qcom,adc-vdd-reference = <0x708>;
					qcom,adc_tm-vadc = <0x82>;
					linux,phandle = <0x83>;
					phandle = <0x83>;

					chan@30 {
						label = "batt_therm";
						reg = <0x30>;
						qcom,decimation = <0x0>;
						qcom,pre-div-channel-scaling = <0x0>;
						qcom,calibration-type = "ratiometric";
						qcom,scale-function = <0x1>;
						qcom,hw-settle-time = <0xb>;
						qcom,fast-avg-setup = <0x3>;
						qcom,btm-channel-number = <0x48>;
					};

					chan@6 {
						label = "vbat_sns";
						reg = <0x6>;
						qcom,decimation = <0x0>;
						qcom,pre-div-channel-scaling = <0x1>;
						qcom,calibration-type = "absolute";
						qcom,scale-function = <0x0>;
						qcom,hw-settle-time = <0xb>;
						qcom,fast-avg-setup = <0x3>;
						qcom,btm-channel-number = <0x68>;
					};
				};

				qcom,charger {
					spmi-dev-container;
					compatible = "qcom,qpnp-linear-charger";
					#address-cells = <0x1>;
					#size-cells = <0x1>;
					qcom,vddmax-mv = <0x1068>;
					qcom,vddsafe-mv = <0x1068>;
					qcom,vinmin-mv = <0x10d4>;
					qcom,ibatsafe-ma = <0x5a0>;
					qcom,thermal-mitigation = <0x5a0 0x2d0 0x276 0x0>;
					qcom,cool-bat-decidegc = <0x64>;
					qcom,warm-bat-decidegc = <0x1c2>;
					qcom,cool-bat-mv = <0x1004>;
					qcom,warm-bat-mv = <0x1004>;
					qcom,ibatmax-warm-ma = <0x168>;
					qcom,ibatmax-cool-ma = <0x168>;
					qcom,batt-hot-percentage = <0x19>;
					qcom,batt-cold-percentage = <0x50>;
					qcom,tchg-mins = <0xe8>;
					qcom,resume-soc = <0x63>;
					qcom,chg-vadc = <0x82>;
					qcom,chg-adc_tm = <0x83>;
					status = "disabled";
					qcom,use-external-charger;

					qcom,chgr@1000 {
						reg = <0x1000 0x100>;
						interrupts = <0x0 0x10 0x7 0x0 0x10 0x6 0x0 0x10 0x5 0x0 0x10 0x0>;
						interrupt-names = "chg-done", "chg-failed", "fast-chg-on", "vbat-det-lo";
					};

					qcom,bat-if@1200 {
						reg = <0x1200 0x100>;
						interrupts = <0x0 0x12 0x1 0x0 0x12 0x0>;
						interrupt-names = "bat-temp-ok", "batt-pres";
					};

					qcom,usb-chgpth@1300 {
						reg = <0x1300 0x100>;
						interrupts = <0x0 0x13 0x4 0x0 0x13 0x2 0x0 0x13 0x1>;
						interrupt-names = "usb-over-temp", "chg-gone", "usbin-valid";
					};

					qcom,chg-misc@1600 {
						reg = <0x1600 0x100>;
					};
				};

				qcom,vmbms {
					spmi-dev-container;
					compatible = "qcom,qpnp-vm-bms";
					#address-cells = <0x1>;
					#size-cells = <0x1>;
					status = "disabled";
					qcom,v-cutoff-uv = <0x33e140>;
					qcom,max-voltage-uv = <0x401640>;
					qcom,r-conn-mohm = <0x0>;
					qcom,shutdown-soc-valid-limit = <0x64>;
					qcom,low-soc-calculate-soc-threshold = <0xf>;
					qcom,low-voltage-calculate-soc-ms = <0x3e8>;
					qcom,low-soc-calculate-soc-ms = <0x1388>;
					qcom,calculate-soc-ms = <0x4e20>;
					qcom,volatge-soc-timeout-ms = <0xea60>;
					qcom,low-voltage-threshold = <0x34a490>;
					qcom,s3-ocv-tolerence-uv = <0x4b0>;
					qcom,s2-fifo-length = <0x5>;
					qcom,low-soc-fifo-length = <0x2>;
					qcom,bms-vadc = <0x82>;
					qcom,bms-adc_tm = <0x83>;
					qcom,pmic-revid = <0x81>;
					qcom,force-s3-on-suspend;
					qcom,force-s2-in-charging;
					qcom,report-charger-eoc;
					qcom,disable-bms;

					qcom,batt-pres-status@1208 {
						reg = <0x1208 0x1>;
					};

					qcom,qpnp-chg-pres@1008 {
						reg = <0x1008 0x1>;
					};

					qcom,vm-bms@4000 {
						reg = <0x4000 0x100>;
						interrupts = <0x0 0x40 0x0 0x0 0x40 0x1 0x0 0x40 0x2 0x0 0x40 0x3 0x0 0x40 0x4 0x0 0x40 0x5>;
						interrupt-names = "leave_cv", "enter_cv", "good_ocv", "ocv_thr", "fifo_update_done", "fsm_state_change";
					};
				};

				qcom,leds@a100 {
					compatible = "qcom,leds-qpnp";
					reg = <0xa100 0x100>;
					label = "mpp";
					status = "okay";

					qcom,led_mpp_2 {
						label = "mpp";
						linux,name = "button-backlight";
						linux,default-trigger = "none";
						qcom,default-state = "off";
						qcom,max-current = <0x28>;
						qcom,current-setting = <0x5>;
						qcom,id = <0x6>;
						qcom,mode = "manual";
						qcom,source-sel = <0x1>;
						qcom,mode-ctrl = <0x60>;
					};
				};
			};

			qcom,pm8916@1 {
				spmi-slave-container;
				reg = <0x1>;
				#address-cells = <0x1>;
				#size-cells = <0x1>;

				regulator@1400 {
					compatible = "qcom,qpnp-regulator";
					regulator-name = "8916_s1";
					spmi-dev-container;
					#address-cells = <0x1>;
					#size-cells = <0x1>;
					reg = <0x1400 0x300>;
					status = "okay";
					qcom,system-load = <0x186a0>;
					qcom,enable-time = <0x1f4>;
					regulator-min-microvolt = <0x13a54c>;
					regulator-max-microvolt = <0x13a54c>;
					regulator-always-on;

					qcom,ctl@1400 {
						reg = <0x1400 0x100>;
					};

					qcom,ps@1500 {
						reg = <0x1500 0x100>;
					};

					qcom,freq@1600 {
						reg = <0x1600 0x100>;
					};
				};

				regulator@1700 {
					compatible = "qcom,qpnp-regulator";
					regulator-name = "8916_s2";
					spmi-dev-container;
					#address-cells = <0x1>;
					#size-cells = <0x1>;
					reg = <0x1700 0x300>;
					status = "okay";
					qcom,system-load = <0x186a0>;
					qcom,enable-time = <0x1f4>;
					regulator-min-microvolt = <0x13a54c>;
					regulator-max-microvolt = <0x13a54c>;
					regulator-always-on;

					qcom,ctl@1700 {
						reg = <0x1700 0x100>;
					};

					qcom,ps@1800 {
						reg = <0x1800 0x100>;
					};

					qcom,freq@1900 {
						reg = <0x1900 0x100>;
					};
				};

				regulator@1a00 {
					compatible = "qcom,qpnp-regulator";
					regulator-name = "8916_s3";
					spmi-dev-container;
					#address-cells = <0x1>;
					#size-cells = <0x1>;
					reg = <0x1a00 0x300>;
					status = "okay";
					qcom,system-load = <0x186a0>;
					qcom,enable-time = <0x1f4>;
					regulator-min-microvolt = <0x13d620>;
					regulator-max-microvolt = <0x13d620>;
					regulator-always-on;
					linux,phandle = <0x84>;
					phandle = <0x84>;

					qcom,ctl@1a00 {
						reg = <0x1a00 0x100>;
					};

					qcom,ps@1b00 {
						reg = <0x1b00 0x100>;
					};

					qcom,freq@1c00 {
						reg = <0x1c00 0x100>;
					};
				};

				regulator@1d00 {
					compatible = "qcom,qpnp-regulator";
					regulator-name = "8916_s4";
					spmi-dev-container;
					#address-cells = <0x1>;
					#size-cells = <0x1>;
					reg = <0x1d00 0x300>;
					status = "okay";
					qcom,system-load = <0x186a0>;
					qcom,enable-time = <0x1f4>;
					regulator-min-microvolt = <0x200b20>;
					regulator-max-microvolt = <0x200b20>;
					regulator-always-on;
					linux,phandle = <0x85>;
					phandle = <0x85>;

					qcom,ctl@1d00 {
						reg = <0x1d00 0x100>;
					};

					qcom,ps@1e00 {
						reg = <0x1e00 0x100>;
					};

					qcom,freq@1f00 {
						reg = <0x1f00 0x100>;
					};
				};

				regulator@4000 {
					compatible = "qcom,qpnp-regulator";
					regulator-name = "8916_l1";
					reg = <0x4000 0x100>;
					status = "okay";
					qcom,enable-time = <0xc8>;
					parent-supply = <0x84>;
					regulator-min-microvolt = <0x12b128>;
					regulator-max-microvolt = <0x12b128>;
				};

				regulator@4100 {
					compatible = "qcom,qpnp-regulator";
					regulator-name = "8916_l2";
					reg = <0x4100 0x100>;
					status = "okay";
					qcom,enable-time = <0xc8>;
					qcom,system-load = <0x2710>;
					parent-supply = <0x84>;
					regulator-min-microvolt = <0x124f80>;
					regulator-max-microvolt = <0x124f80>;
					regulator-always-on;
				};

				regulator@4200 {
					compatible = "qcom,qpnp-regulator";
					regulator-name = "8916_l3";
					reg = <0x4200 0x100>;
					status = "okay";
					qcom,enable-time = <0xc8>;
					qcom,system-load = <0x2710>;
					parent-supply = <0x84>;
					regulator-min-microvolt = <0x13a54c>;
					regulator-max-microvolt = <0x13a54c>;
					regulator-always-on;
				};

				regulator@4300 {
					compatible = "qcom,qpnp-regulator";
					regulator-name = "8916_l4";
					reg = <0x4300 0x100>;
					status = "okay";
					qcom,enable-time = <0xc8>;
					parent-supply = <0x85>;
					regulator-min-microvolt = <0x1f47d0>;
					regulator-max-microvolt = <0x1f47d0>;
				};

				regulator@4400 {
					compatible = "qcom,qpnp-regulator";
					regulator-name = "8916_l5";
					reg = <0x4400 0x100>;
					status = "okay";
					qcom,enable-time = <0xc8>;
					qcom,system-load = <0x2710>;
					parent-supply = <0x85>;
					regulator-min-microvolt = <0x1b7740>;
					regulator-max-microvolt = <0x1b7740>;
					regulator-always-on;
					linux,phandle = <0x87>;
					phandle = <0x87>;
				};

				regulator@4500 {
					compatible = "qcom,qpnp-regulator";
					regulator-name = "8916_l6";
					reg = <0x4500 0x100>;
					status = "okay";
					qcom,enable-time = <0xc8>;
					parent-supply = <0x85>;
					regulator-min-microvolt = <0x1b7740>;
					regulator-max-microvolt = <0x1b7740>;
					linux,phandle = <0x70>;
					phandle = <0x70>;
				};

				regulator@4600 {
					compatible = "qcom,qpnp-regulator";
					regulator-name = "8916_l7";
					reg = <0x4600 0x100>;
					status = "okay";
					qcom,enable-time = <0xc8>;
					parent-supply = <0x85>;
					regulator-min-microvolt = <0x1b7740>;
					regulator-max-microvolt = <0x1b7740>;
					linux,phandle = <0x67>;
					phandle = <0x67>;
				};

				regulator@4700 {
					compatible = "qcom,qpnp-regulator";
					regulator-name = "8916_l8";
					reg = <0x4700 0x100>;
					status = "okay";
					qcom,enable-time = <0xc8>;
					regulator-min-microvolt = <0x2b7cd0>;
					regulator-max-microvolt = <0x2c4020>;
				};

				regulator@4800 {
					compatible = "qcom,qpnp-regulator";
					regulator-name = "8916_l9";
					reg = <0x4800 0x100>;
					status = "okay";
					qcom,enable-time = <0xc8>;
					regulator-min-microvolt = <0x325aa0>;
					regulator-max-microvolt = <0x325aa0>;
				};

				regulator@4900 {
					compatible = "qcom,qpnp-regulator";
					regulator-name = "8916_l10";
					reg = <0x4900 0x100>;
					status = "okay";
					qcom,enable-time = <0xc8>;
					regulator-min-microvolt = <0x2932e0>;
					regulator-max-microvolt = <0x2ab980>;
				};

				regulator@4a00 {
					compatible = "qcom,qpnp-regulator";
					regulator-name = "8916_l11";
					reg = <0x4a00 0x100>;
					status = "okay";
					qcom,enable-time = <0xc8>;
					regulator-min-microvolt = <0x1b7740>;
					regulator-max-microvolt = <0x2d0370>;
				};

				regulator@4b00 {
					compatible = "qcom,qpnp-regulator";
					regulator-name = "8916_l12";
					reg = <0x4b00 0x100>;
					status = "okay";
					qcom,enable-time = <0xc8>;
					regulator-min-microvolt = <0x1b7740>;
					regulator-max-microvolt = <0x2d0370>;
				};

				regulator@4c00 {
					compatible = "qcom,qpnp-regulator";
					regulator-name = "8916_l13";
					reg = <0x4c00 0x100>;
					status = "okay";
					qcom,enable-time = <0xc8>;
					regulator-min-microvolt = <0x2eebb8>;
					regulator-max-microvolt = <0x2eebb8>;
					linux,phandle = <0x68>;
					phandle = <0x68>;
				};

				regulator@4d00 {
					compatible = "qcom,qpnp-regulator";
					regulator-name = "8916_l14";
					reg = <0x4d00 0x100>;
					status = "okay";
					qcom,enable-time = <0xc8>;
					qcom,system-load = <0x1388>;
					regulator-min-microvolt = <0x1b7740>;
					regulator-max-microvolt = <0x325aa0>;
				};

				regulator@4e00 {
					compatible = "qcom,qpnp-regulator";
					regulator-name = "8916_l15";
					reg = <0x4e00 0x100>;
					status = "okay";
					qcom,enable-time = <0xc8>;
					regulator-min-microvolt = <0x1b7740>;
					regulator-max-microvolt = <0x325aa0>;
				};

				regulator@4f00 {
					compatible = "qcom,qpnp-regulator";
					regulator-name = "8916_l16";
					reg = <0x4f00 0x100>;
					status = "okay";
					qcom,enable-time = <0xc8>;
					regulator-min-microvolt = <0x1b7740>;
					regulator-max-microvolt = <0x325aa0>;
					linux,phandle = <0x77>;
					phandle = <0x77>;
				};

				regulator@5000 {
					compatible = "qcom,qpnp-regulator";
					regulator-name = "8916_l17";
					reg = <0x5000 0x100>;
					status = "okay";
					qcom,enable-time = <0xc8>;
					regulator-min-microvolt = <0x2932e0>;
					regulator-max-microvolt = <0x2b7cd0>;
					linux,phandle = <0x6f>;
					phandle = <0x6f>;
				};

				regulator@5100 {
					compatible = "qcom,qpnp-regulator";
					regulator-name = "8916_l18";
					reg = <0x5100 0x100>;
					status = "okay";
					qcom,enable-time = <0xc8>;
					regulator-min-microvolt = <0x2932e0>;
					regulator-max-microvolt = <0x2932e0>;
				};

				pwm@bc00 {
					compatible = "qcom,qpnp-pwm";
					reg = <0xbc00 0x100>;
					reg-names = "qpnp-lpg-channel-base";
					qcom,channel-id = <0x0>;
					qcom,supported-sizes = <0x6 0x9>;
				};

				qcom,vibrator@c000 {
					compatible = "qcom,qpnp-vibrator";
					reg = <0xc000 0x100>;
					label = "vibrator";
					status = "okay";
					qcom,vib-timeout-ms = <0x3a98>;
					qcom,vib-vtg-level-mV = <0xc1c>;
				};

				msm8x16_wcd_codec@f000 {
					compatible = "qcom,wcd-spmi";
					reg = <0xf000 0x100>;
					interrupt-parent = <0x86>;
					interrupts = <0x1 0xf0 0x0 0x1 0xf0 0x1 0x1 0xf0 0x2 0x1 0xf0 0x3 0x1 0xf0 0x4 0x1 0xf0 0x5 0x1 0xf0 0x6 0x1 0xf0 0x7>;
					interrupt-names = "spk_cnp_int", "spk_clip_int", "spk_ocp_int", "ins_rem_det1", "but_rel_det", "but_press_det", "ins_rem_det", "mbhc_int";
					cdc-vdda-cp-supply = <0x85>;
					qcom,cdc-vdda-cp-voltage = <0x1b7740 0x2191c0>;
					qcom,cdc-vdda-cp-current = <0xbbfd0>;
					cdc-vdda-h-supply = <0x87>;
					qcom,cdc-vdda-h-voltage = <0x1b7740 0x1b7740>;
					qcom,cdc-vdda-h-current = <0x4e20>;
					cdc-vdd-px-supply = <0x85>;
					qcom,cdc-vdd-px-voltage = <0x1b7740 0x2191c0>;
					qcom,cdc-vdd-px-current = <0xbbfd0>;
					cdc-vdd-pa-supply = <0x87>;
					qcom,cdc-vdd-pa-voltage = <0x1b7740 0x1b7740>;
					qcom,cdc-vdd-pa-current = <0x1388>;
					cdc-vdd-mic-bias-supply = <0x68>;
					qcom,cdc-vdd-mic-bias-voltage = <0x2eebb8 0x2eebb8>;
					qcom,cdc-vdd-mic-bias-current = <0x61a8>;
					qcom,cdc-mclk-clk-rate = <0x927c00>;
					qcom,cdc-static-supplies = "cdc-vdda-h", "cdc-vdd-px", "cdc-vdd-pa", "cdc-vdda-cp";
					qcom,cdc-on-demand-supplies = "cdc-vdd-mic-bias";
				};

				msm8x16_wcd_codec@f100 {
					compatible = "qcom,wcd-spmi";
					reg = <0xf100 0x100>;
					interrupt-parent = <0x86>;
					interrupts = <0x1 0xf1 0x0 0x1 0xf1 0x1 0x1 0xf1 0x2 0x1 0xf1 0x3 0x1 0xf1 0x4 0x1 0xf1 0x5>;
					interrupt-names = "ear_ocp_int", "hphr_ocp_int", "hphl_ocp_det", "ear_cnp_int", "hphr_cnp_int", "hphl_cnp_int";
				};

				qpnp-buck-current-monitor@1800 {
					compatible = "qcom,qpnp-buck-current-monitor";
					reg = <0x1800 0x100>;
					interrupts = <0x1 0x18 0x0 0x1 0x18 0x1>;
					interrupt-names = "iwarning", "icritical";
					qcom,enable-current-monitor;
					qcom,icrit-init-threshold-pc = <0x5a>;
					qcom,iwarn-init-threshold-pc = <0x46>;
					qcom,icrit-polling-delay-msec = <0x3e8>;
					qcom,iwarn-polling-delay-msec = <0x7d0>;
					status = "disabled";
				};
			};
		};

		rmtfs_sharedmem {
			compatible = "qcom,sharedmem-uio";
			reg = <0x8e580000 0x160000>;
			reg-names = "rmtfs";
		};

		dsp_sharedmem {
			compatible = "qcom,sharedmem-uio";
			reg = <0x8e6e0000 0x20000>;
			reg-names = "rfsa_dsp";
		};

		mdm_sharedmem {
			compatible = "qcom,sharedmem-uio";
			reg = <0x8e6e0000 0x20000>;
			reg-names = "rfsa_mdm";
		};

		sdhci@7824000 {
			compatible = "qcom,sdhci-msm";
			reg = <0x7824900 0x11c 0x7824000 0x800>;
			reg-names = "hc_mem", "core_mem";
			interrupts = <0x0 0x7b 0x0 0x0 0x8a 0x0>;
			interrupt-names = "hc_irq", "pwr_irq";
			qcom,bus-width = <0x8>;
			qcom,cpu-dma-latency-us = <0x2bd>;
			clocks = <0x1c 0x691e0caa 0x1c 0x9ad6fb96>;
			clock-names = "iface_clk", "core_clk";
			qcom,clk-rates = <0x61a80 0x17d7840 0x2faf080 0x5f5e100 0xbebc200>;
			qcom,bus-speed-mode = "HS200_1p8v", "DDR_1p8v";
			status = "disabled";
		};

		sdhci@7864000 {
			compatible = "qcom,sdhci-msm";
			reg = <0x7864900 0x11c 0x7864000 0x800>;
			reg-names = "hc_mem", "core_mem";
			interrupts = <0x0 0x1>;
			interrupt-names = "hc_irq", "pwr_irq";
			qcom,bus-width = <0x4>;
			qcom,cpu-dma-latency-us = <0x2bd>;
			clocks = <0x1c 0x23d5727f 0x1c 0x861b20ac>;
			clock-names = "iface_clk", "core_clk";
			qcom,clk-rates = <0x61a80 0x17d7840 0x2faf080 0x5f5e100 0xbebc200>;
			status = "disabled";
			qcom,nonremovable;
			interrupt-map = <0x0 0x1 0x0 0x7d 0x0 0x1 0x1 0x0 0xdd 0x0>;
		};

		qcom,msm-imem@8600000 {
			compatible = "qcom,msm-imem";
			reg = <0x8600000 0x1000>;
			ranges = <0x0 0x8600000 0x1000>;
			#address-cells = <0x1>;
			#size-cells = <0x1>;

			mem_dump_table@10 {
				compatible = "qcom,msm-imem-mem_dump_table";
				reg = <0x10 0x8>;
			};
		};

		qcom,venus@1de0000 {
			compatible = "qcom,pil-tz-generic";
			reg = <0x1de0000 0x4000>;
			vdd-supply = <0x88>;
			proxy-reg-names = "vdd";
			clocks = <0x1c 0xf76a02bb 0x1c 0x8d778c6 0x1c 0xcdf4c8f6>;
			clock-names = "core_clk", "iface_clk", "bus_clk";
			proxy-clock-names = "core_clk", "iface_clk", "bus_clk";
			qcom,pas-id = <0x9>;
			qcom,proxy-timeout-ms = <0x1388>;
			qcom,firmware-name = "venus";
		};

		qcom,msm-pcm {
			compatible = "qcom,msm-pcm-dsp";
			qcom,msm-pcm-dsp-id = <0x0>;
		};

		qcom,msm-pcm-routing {
			compatible = "qcom,msm-pcm-routing";
		};

		qcom,msm-pcm-low-latency {
			compatible = "qcom,msm-pcm-dsp";
			qcom,msm-pcm-dsp-id = <0x1>;
			qcom,msm-pcm-low-latency;
			qcom,latency-level = "ultra";
		};

		qcom,msm-pcm-lpa {
			compatible = "qcom,msm-pcm-lpa";
		};

		qcom,msm-compress-dsp {
			compatible = "qcom,msm-compress-dsp";
		};

		qcom,msm-voip-dsp {
			compatible = "qcom,msm-voip-dsp";
		};

		qcom,msm-pcm-voice {
			compatible = "qcom,msm-pcm-voice";
			qcom,destroy-cvd;
		};

		qcom,msm-stub-codec {
			compatible = "qcom,msm-stub-codec";
		};

		qcom,msm-dai-fe {
			compatible = "qcom,msm-dai-fe";
		};

		qcom,msm-pcm-afe {
			compatible = "qcom,msm-pcm-afe";
		};

		qcom,msm-voice-svc {
			compatible = "qcom,msm-voice-svc";
		};

		qcom,msm-pcm-loopback {
			compatible = "qcom,msm-pcm-loopback";
		};

		qcom,msm-dai-mi2s {
			compatible = "qcom,msm-dai-mi2s";

			qcom,msm-dai-q6-mi2s-prim {
				compatible = "qcom,msm-dai-q6-mi2s";
				qcom,msm-dai-q6-mi2s-dev-id = <0x0>;
				qcom,msm-mi2s-rx-lines = <0x3>;
				qcom,msm-mi2s-tx-lines = <0x0>;
			};

			qcom,msm-dai-q6-mi2s-sec {
				compatible = "qcom,msm-dai-q6-mi2s";
				qcom,msm-dai-q6-mi2s-dev-id = <0x1>;
				qcom,msm-mi2s-rx-lines = <0x1>;
				qcom,msm-mi2s-tx-lines = <0x0>;
			};

			qcom,msm-dai-q6-mi2s-tert {
				compatible = "qcom,msm-dai-q6-mi2s";
				qcom,msm-dai-q6-mi2s-dev-id = <0x2>;
				qcom,msm-mi2s-rx-lines = <0x0>;
				qcom,msm-mi2s-tx-lines = <0x3>;
			};
		};

		qcom,msm-dai-q6-hdmi {
			compatible = "qcom,msm-dai-q6-hdmi";
			qcom,msm-dai-q6-dev-id = <0x8>;
		};

		qcom,msm-lsm-client {
			compatible = "qcom,msm-lsm-client";
		};

		qcom,msm-dai-q6 {
			compatible = "qcom,msm-dai-q6";

			qcom,msm-dai-q6-sb-0-rx {
				compatible = "qcom,msm-dai-q6-dev";
				qcom,msm-dai-q6-dev-id = <0x4000>;
			};

			qcom,msm-dai-q6-sb-0-tx {
				compatible = "qcom,msm-dai-q6-dev";
				qcom,msm-dai-q6-dev-id = <0x4001>;
			};

			qcom,msm-dai-q6-sb-1-rx {
				compatible = "qcom,msm-dai-q6-dev";
				qcom,msm-dai-q6-dev-id = <0x4002>;
			};

			qcom,msm-dai-q6-sb-1-tx {
				compatible = "qcom,msm-dai-q6-dev";
				qcom,msm-dai-q6-dev-id = <0x4003>;
			};

			qcom,msm-dai-q6-sb-3-rx {
				compatible = "qcom,msm-dai-q6-dev";
				qcom,msm-dai-q6-dev-id = <0x4006>;
			};

			qcom,msm-dai-q6-sb-3-tx {
				compatible = "qcom,msm-dai-q6-dev";
				qcom,msm-dai-q6-dev-id = <0x4007>;
			};

			qcom,msm-dai-q6-sb-4-rx {
				compatible = "qcom,msm-dai-q6-dev";
				qcom,msm-dai-q6-dev-id = <0x4008>;
			};

			qcom,msm-dai-q6-sb-4-tx {
				compatible = "qcom,msm-dai-q6-dev";
				qcom,msm-dai-q6-dev-id = <0x4009>;
			};

			qcom,msm-dai-q6-bt-sco-rx {
				compatible = "qcom,msm-dai-q6-dev";
				qcom,msm-dai-q6-dev-id = <0x3000>;
			};

			qcom,msm-dai-q6-bt-sco-tx {
				compatible = "qcom,msm-dai-q6-dev";
				qcom,msm-dai-q6-dev-id = <0x3001>;
			};

			qcom,msm-dai-q6-int-fm-rx {
				compatible = "qcom,msm-dai-q6-dev";
				qcom,msm-dai-q6-dev-id = <0x3004>;
			};

			qcom,msm-dai-q6-int-fm-tx {
				compatible = "qcom,msm-dai-q6-dev";
				qcom,msm-dai-q6-dev-id = <0x3005>;
			};

			qcom,msm-dai-q6-be-afe-pcm-rx {
				compatible = "qcom,msm-dai-q6-dev";
				qcom,msm-dai-q6-dev-id = <0xe0>;
			};

			qcom,msm-dai-q6-be-afe-pcm-tx {
				compatible = "qcom,msm-dai-q6-dev";
				qcom,msm-dai-q6-dev-id = <0xe1>;
			};

			qcom,msm-dai-q6-afe-proxy-rx {
				compatible = "qcom,msm-dai-q6-dev";
				qcom,msm-dai-q6-dev-id = <0xf1>;
			};

			qcom,msm-dai-q6-afe-proxy-tx {
				compatible = "qcom,msm-dai-q6-dev";
				qcom,msm-dai-q6-dev-id = <0xf0>;
			};

			qcom,msm-dai-q6-incall-record-rx {
				compatible = "qcom,msm-dai-q6-dev";
				qcom,msm-dai-q6-dev-id = <0x8003>;
			};

			qcom,msm-dai-q6-incall-record-tx {
				compatible = "qcom,msm-dai-q6-dev";
				qcom,msm-dai-q6-dev-id = <0x8004>;
			};

			qcom,msm-dai-q6-incall-music-rx {
				compatible = "qcom,msm-dai-q6-dev";
				qcom,msm-dai-q6-dev-id = <0x8005>;
			};

			qcom,msm-dai-q6-incall-music-2-rx {
				compatible = "qcom,msm-dai-q6-dev";
				qcom,msm-dai-q6-dev-id = <0x8002>;
			};
		};

		qcom,msm-pcm-hostless {
			compatible = "qcom,msm-pcm-hostless";
		};

		qcom,vidc@1d00000 {
			compatible = "qcom,msm-vidc";
			reg = <0x1d00000 0xff000>;
			interrupts = <0x0 0x2c 0x0>;
			venus-supply = <0x88>;
			venus-core0-supply = <0x89>;
			venus-core1-supply = <0x8a>;
			clocks = <0x1c 0xf76a02bb 0x1c 0x83a7f549 0x1c 0xa0813de6 0x1c 0x8d778c6 0x1c 0xcdf4c8f6>;
			clock-names = "core_clk", "core0_clk", "core1_clk", "iface_clk", "bus_clk";
			qcom,clock-names = "core_clk", "core0_clk", "core1_clk", "iface_clk", "bus_clk";
			qcom,clock-configs = <0x3 0x0 0x0 0x0 0x0>;
			qcom,load-freq-tbl = <0x56220 0xd9fb390 0x3bc40 0x9896800 0x1a5e0 0x5f5e100>;
			qcom,hfi = "venus";
			qcom,reg-presets = <0xe0020 0xaaaaaaa 0xe0024 0xaaaaaaa 0x80124 0x3>;
			qcom,buffer-type-tz-usage-table = <0x241 0x1 0x106 0x2 0x480 0x3>;
			qcom,max-hw-load = <0x77880>;

			qcom,vidc-iommu-domains {

				qcom,domain-ns {
					qcom,vidc-domain-phandle = <0x8b>;
					qcom,vidc-partition-buffer-types = <0x7ff 0x800>;
				};

				qcom,domain-sec-bs {
					qcom,vidc-domain-phandle = <0x8c>;
					qcom,vidc-partition-buffer-types = <0x241>;
				};

				qcom,domain-sec-px {
					qcom,vidc-domain-phandle = <0x8d>;
					qcom,vidc-partition-buffer-types = <0x106>;
				};

				qcom,domain-sec-np {
					qcom,vidc-domain-phandle = <0x8e>;
					qcom,vidc-partition-buffer-types = <0x480>;
				};
			};

			qcom,msm-bus-clients {

				qcom,msm-bus-client@0 {
					qcom,msm-bus,name = "venc-ddr";
					qcom,msm-bus,num-cases = <0x4>;
					qcom,msm-bus,num-paths = <0x1>;
					qcom,msm-bus,vectors-KBps = <0x3f 0x200 0x0 0x0 0x3f 0x200 0x209e0 0xa4a60 0x3f 0x200 0x61e04 0x1076d8 0x3f 0x200 0xddd38 0x177640>;
					qcom,bus-configs = <0x1000414>;
				};

				qcom,msm-bus-client@1 {
					qcom,msm-bus,name = "vdec-core0-ddr";
					qcom,msm-bus,num-cases = <0x4>;
					qcom,msm-bus,num-paths = <0x1>;
					qcom,msm-bus,vectors-KBps = <0x3f 0x200 0x0 0x0 0x3f 0x200 0x18510 0xcb19c 0x3f 0x200 0x48f94 0xcb19c 0x3f 0x200 0xa56e0 0x144f38>;
					qcom,bus-configs = <0x30fcfff>;
				};

				qcom,msm-bus-client@2 {
					qcom,msm-bus,name = "vdec-core1-ddr";
					qcom,msm-bus,num-cases = <0x4>;
					qcom,msm-bus,num-paths = <0x1>;
					qcom,msm-bus,vectors-KBps = <0x3f 0x200 0x0 0x0 0x3f 0x200 0x18510 0xcb19c 0x3f 0x200 0x48f94 0xcb19c 0x3f 0x200 0xa56e0 0x144f38>;
					qcom,bus-configs = <0xc000000>;
				};
			};
		};

		qcom,avtimer {
			compatible = "qcom,avtimer";
			reg = <0xfe053008 0x4 0xfe05300c 0x4>;
			reg-names = "avtimer_lsb_addr", "avtimer_msb_addr";
		};

		pinctrl@1000000 {
			compatible = "qcom,msm-tlmm-v4";
			reg = <0x1000000 0x300000>;
			interrupts = <0x0 0xd0 0x0>;

			gp {
				qcom,pin-type-gp;
				qcom,num-pins = <0x7a>;
				#qcom,pin-cells = <0x1>;
				linux,phandle = <0x8f>;
				phandle = <0x8f>;

				msm_gpio {
					compatible = "qcom,msm-tlmmv4-gp-intc";
					gpio-controller;
					#gpio-cells = <0x2>;
					interrupt-controller;
					#interrupt-cells = <0x2>;
					num_irqs = <0x7a>;
					linux,phandle = <0x6e>;
					phandle = <0x6e>;
				};
			};

			pmx-uartconsole {
				qcom,pins = <0x8f 0x4 0x8f 0x5>;
				qcom,num-grp-pins = <0x2>;
				qcom,pin-func = <0x2>;
				label = "uart-console";

				uart-console {
					drive-strength = <0x2>;
					bias-pull-down;
					linux,phandle = <0x69>;
					phandle = <0x69>;
				};
			};

			sdhc2_cd_pin {
				qcom,pins = <0x8f 0x26>;
				qcom,num-grp-pins = <0x1>;
				qcom,pin-func = <0x0>;
				label = "cd-gpio";

				cd_on {
					drive-strength = <0x2>;
					bias-pull-up;
				};

				cd_off {
					drive-strength = <0x2>;
					bias-disable;
				};
			};

			sdc {
				qcom,pin-type-sdc;
				qcom,num-pins = <0x7>;
				#qcom,pin-cells = <0x1>;
				linux,phandle = <0x90>;
				phandle = <0x90>;
			};

			pmx_sdc1_clk {
				qcom,pins = <0x90 0x0>;
				qcom,num-grp-pins = <0x1>;
				label = "sdc1-clk";

				clk_on {
					bias-disable;
					drive-strength = <0x10>;
				};

				clk_off {
					bias-disable;
					drive-strength = <0x2>;
				};
			};

			pmx_sdc1_cmd {
				qcom,pins = <0x90 0x1>;
				qcom,num-grp-pins = <0x1>;
				label = "sdc1-cmd";

				cmd_on {
					bias-pull-up;
					drive-strength = <0xa>;
				};

				cmd_off {
					bias-pull-up;
					drive-strength = <0x2>;
				};
			};

			pmx_sdc1_data {
				qcom,pins = <0x90 0x2>;
				qcom,num-grp-pins = <0x1>;
				label = "sdc1-data";

				data_on {
					bias-pull-up;
					drive-strength = <0xa>;
				};

				data_off {
					bias-pull-up;
					drive-strength = <0x2>;
				};
			};

			pmx_sdc2_clk {
				qcom,pins = <0x90 0x4>;
				qcom,num-grp-pins = <0x1>;
				label = "sdc2-clk";

				clk_on {
					bias-disable;
					drive-strength = <0x10>;
				};

				clk_off {
					bias-disable;
					drive-strength = <0x2>;
				};
			};

			pmx_sdc2_cmd {
				qcom,pins = <0x90 0x5>;
				qcom,num-grp-pins = <0x1>;
				label = "sdc2-cmd";

				cmd_on {
					bias-pull-up;
					drive-strength = <0xa>;
				};

				cmd_off {
					bias-pull-up;
					drive-strength = <0x2>;
				};
			};

			pmx_sdc2_data {
				qcom,pins = <0x90 0x6>;
				qcom,num-grp-pins = <0x1>;
				label = "sdc2-data";

				data_on {
					bias-pull-up;
					drive-strength = <0xa>;
				};

				data_off {
					bias-pull-up;
					drive-strength = <0x2>;
				};
			};

			pmx_i2c_0 {
				qcom,pins = <0x8f 0x7 0x8f 0x6>;
				qcom,num-grp-pins = <0x2>;
				qcom,pin-func = <0x3>;
				label = "pmx_i2c_0";

				i2c_0_active {
					drive-strength = <0x2>;
					bias-disable;
					linux,phandle = <0x6a>;
					phandle = <0x6a>;
				};

				i2c_0_sleep {
					drive-strength = <0x2>;
					bias-disable;
					linux,phandle = <0x6b>;
					phandle = <0x6b>;
				};
			};

			pmx_i2c_4 {
				qcom,pins = <0x8f 0xe 0x8f 0xf>;
				qcom,num-grp-pins = <0x2>;
				qcom,pin-func = <0x2>;
				label = "pmx_i2c_4";

				i2c_4_active {
					drive-strength = <0x2>;
					bias-disable;
					linux,phandle = <0x7d>;
					phandle = <0x7d>;
				};

				i2c_4_sleep {
					drive-strength = <0x2>;
					bias-disable;
					linux,phandle = <0x7e>;
					phandle = <0x7e>;
				};
			};

			smb_int_pin {
				qcom,pins = <0x8f 0x3e>;
				qcom,num-grp-pins = <0x1>;
				qcom,pin-func = <0x0>;
				label = "smb1360_int_gpio";

				smb_int_default {
					drive-strength = <0x2>;
					bias-pull-up;
					linux,phandle = <0x80>;
					phandle = <0x80>;
				};
			};

			spi0_active {
				qcom,pins = <0x8f 0x8 0x8f 0x9 0x8f 0xb>;
				qcom,num-grp-pins = <0x3>;
				qcom,pin-func = <0x1>;
				label = "spi0-active";

				default {
					drive-strength = <0xc>;
					bias-disable = <0x0>;
					linux,phandle = <0x79>;
					phandle = <0x79>;
				};
			};

			spi0_suspend {
				qcom,pins = <0x8f 0x8 0x8f 0x9 0x8f 0xb>;
				qcom,num-grp-pins = <0x3>;
				qcom,pin-func = <0x0>;
				label = "spi0-suspend";

				sleep {
					drive-strength = <0x2>;
					bias-disable = <0x0>;
					linux,phandle = <0x7b>;
					phandle = <0x7b>;
				};
			};

			spi0_cs0_active {
				qcom,pins = <0x8f 0xa>;
				qcom,num-grp-pins = <0x1>;
				qcom,pin-func = <0x1>;
				label = "spi0-cs0-active";

				cs0_active {
					drive-strength = <0x2>;
					bias-disable = <0x0>;
					linux,phandle = <0x7a>;
					phandle = <0x7a>;
				};
			};

			spi0_cs0_suspend {
				qcom,pins = <0x8f 0xa>;
				qcom,num-grp-pins = <0x1>;
				qcom,pin-func = <0x0>;
				label = "spi0-cs0-suspend";

				cs0_sleep {
					drive-strength = <0x2>;
					bias-disable = <0x0>;
					linux,phandle = <0x7c>;
					phandle = <0x7c>;
				};
			};

			apds99xx_int_pin {
				qcom,pins = <0x8f 0x71>;
				qcom,pin-func = <0x0>;
				qcom,num-grp-pins = <0x1>;
				label = "apds99xx-irq";

				apds99xx_default {
					drive-strength = <0x6>;
					bias-pull-up;
					linux,phandle = <0x6c>;
					phandle = <0x6c>;
				};

				apds99xx_sleep {
					drive-strength = <0x2>;
					bias-pull-down;
					linux,phandle = <0x6d>;
					phandle = <0x6d>;
				};
			};

			mpu6050_int_pin {
				qcom,pins = <0x8f 0x73>;
				qcom,pin-func = <0x0>;
				qcom,num-grp-pins = <0x1>;
				label = "mpu6050-irq";

				mpu6050_default {
					drive-strength = <0x6>;
					bias-pull-up;
					linux,phandle = <0x75>;
					phandle = <0x75>;
				};

				mpu6050_sleep {
					drive-strength = <0x2>;
					bias-pull-down;
					linux,phandle = <0x76>;
					phandle = <0x76>;
				};
			};

			tlmm_gpio_key {
				qcom,pins = <0x8f 0x6b 0x8f 0x6c 0x8f 0x6d>;
				qcom,pin-func = <0x0>;
				qcom,num-grp-pins = <0x3>;
				label = "tlmm_gpio_key";

				gpio_key_active {
					drive-strength = <0x2>;
					bias-pull-up;
					linux,phandle = <0x91>;
					phandle = <0x91>;
				};

				gpio_key_suspend {
					drive-strength = <0x2>;
					bias-pull-up;
					linux,phandle = <0x92>;
					phandle = <0x92>;
				};
			};

			pmx_ts_int_active {
				qcom,pins = <0x8f 0xd>;
				qcom,pin-func = <0x0>;
				qcom,num-grp-pins = <0x1>;
				label = "pmx_ts_int_active";

				ts_int_active {
					drive-strength = <0x10>;
					bias-pull-up;
					linux,phandle = <0x93>;
					phandle = <0x93>;
				};
			};

			pmx_ts_int_suspend {
				qcom,pins = <0x8f 0xd>;
				qcom,pin-func = <0x0>;
				qcom,num-grp-pins = <0x1>;
				label = "pmx_ts_int_suspend";

				ts_int_suspend {
					drive-strength = <0x2>;
					bias-pull-down;
					linux,phandle = <0x95>;
					phandle = <0x95>;
				};
			};

			pmx_ts_reset_active {
				qcom,pins = <0x8f 0xc>;
				qcom,pin-func = <0x0>;
				qcom,num-grp-pins = <0x1>;
				label = "pmx_ts_reset_active";

				ts_reset_active {
					drive-strength = <0x10>;
					bias-pull-up;
					linux,phandle = <0x94>;
					phandle = <0x94>;
				};
			};

			pmx_ts_reset_suspend {
				qcom,pins = <0x8f 0xc>;
				qcom,pin-func = <0x0>;
				qcom,num-grp-pins = <0x1>;
				label = "pmx_ts_reset_suspend";

				ts_reset_suspend {
					drive-strength = <0x2>;
					bias-pull-down;
					linux,phandle = <0x96>;
					phandle = <0x96>;
				};
			};

			pmx_ts_release {
				qcom,pins = <0x8f 0xd 0x8f 0xc>;
				qcom,num-grp-pins = <0x2>;
				label = "pmx_ts_release";

				ts_release {
					drive-strength = <0x2>;
					bias-pull-down;
					linux,phandle = <0x97>;
					phandle = <0x97>;
				};
			};

			cdc-pdm-lines {
				qcom,pins = <0x8f 0x3f 0x8f 0x40 0x8f 0x41 0x8f 0x42 0x8f 0x43 0x8f 0x44>;
				qcom,num-grp-pins = <0x6>;
				qcom,pin-func = <0x1>;
				label = "cdc-pdm-lines";

				pdm_lines_on {
					drive-strength = <0x8>;
					bias-pull-none;
					linux,phandle = <0x98>;
					phandle = <0x98>;
				};

				pdm_lines_off {
					drive-strength = <0x2>;
					bias-disable;
					linux,phandle = <0x99>;
					phandle = <0x99>;
				};
			};

			cross-conn-det {
				qcom,pins = <0x8f 0x78>;
				qcom,num-grp-pins = <0x1>;
				qcom,pin-func = <0x0>;
				label = "cross-conn-det-sw";

				lines_on {
					drive-strength = <0x8>;
					bias-pull-none;
				};

				lines_off {
					drive-strength = <0x2>;
					bias-disable;
				};
			};

			ext_buck_vsel {
				qcom,pins = <0x8f 0x6f>;
				qcom,num-grp-pins = <0x1>;
				qcom,pin-func = <0x0>;
				label = "ext-buck-vsel";

				vsel0 {
					drive-strength = <0x2>;
					linux,phandle = <0x7f>;
					phandle = <0x7f>;
				};
			};

			bma2x2_int1_pin {
				qcom,pins = <0x8f 0x70>;
				qcom,num-grp-pins = <0x1>;
				label = "bma2x2_int1_pin";

				int1_default {
					drive-strength = <0x6>;
					bias-pull-up;
					linux,phandle = <0x71>;
					phandle = <0x71>;
				};

				int1_sleep {
					drive-strength = <0x2>;
					bias-pull-down;
					linux,phandle = <0x73>;
					phandle = <0x73>;
				};
			};

			bma2x2_int2_pin {
				qcom,pins = <0x8f 0x72>;
				qcom,num-grp-pins = <0x1>;
				label = "bma2x2_int2_pin";

				int2_default {
					drive-strength = <0x6>;
					bias-pull-up;
					linux,phandle = <0x72>;
					phandle = <0x72>;
				};

				int2_sleep {
					drive-strength = <0x2>;
					bias-pull-down;
					linux,phandle = <0x74>;
					phandle = <0x74>;
				};
			};

			tps65132-en-pin {
				qcom,pins = <0x8f 0x61 0x8f 0x62>;
				qcom,num-grp-pins = <0x2>;
				label = "tps65132_en_pins";
				qcom,pin-func = <0x0>;

				en-default {
					drive-strength = <0x2>;
					bias-disable;
					linux,phandle = <0x78>;
					phandle = <0x78>;
				};
			};
		};

		gpio_keys {
			compatible = "gpio-keys";
			input-name = "gpio-keys";
			pinctrl-names = "tlmm_gpio_key_active", "tlmm_gpio_key_suspend";
			pinctrl-0 = <0x91>;
			pinctrl-1 = <0x92>;

			vol_up {
				label = "volume_up";
				gpios = <0x6e 0x6b 0x1>;
				linux,input-type = <0x1>;
				linux,code = <0x73>;
				gpio-key,wakeup;
				debounce-interval = <0xf>;
			};
		};

		i2c@78b9000 {

			focaltech@38 {
				compatible = "focaltech,5x06";
				reg = <0x38>;
				interrupt-parent = <0x6e>;
				interrupts = <0xd 0x2008>;
				vdd-supply = <0x6f>;
				vcc_i2c-supply = <0x70>;
				pinctrl-names = "pmx_ts_active", "pmx_ts_suspend", "pmx_ts_release";
				pinctrl-0 = <0x93 0x94>;
				pinctrl-1 = <0x95 0x96>;
				pinctrl-2 = <0x97>;
				focaltech,name = "ft5336";
				focaltech,family-id = <0x14>;
				focaltech,reset-gpio = <0x6e 0xc 0x0>;
				focaltech,irq-gpio = <0x6e 0xd 0x2008>;
				focaltech,display-coords = <0x0 0x0 0x438 0x780>;
				focaltech,panel-coords = <0x0 0x0 0x438 0x832>;
				focaltech,button-map = <0x8b 0x66 0x9e>;
				focaltech,no-force-update;
				focaltech,i2c-pull-up;
				focaltech,group-id = <0x1>;
				focaltech,hard-reset-delay-ms = <0x14>;
				focaltech,soft-reset-delay-ms = <0xc8>;
				focaltech,num-max-touches = <0x5>;
				focaltech,fw-delay-aa-ms = <0x1e>;
				focaltech,fw-delay-55-ms = <0x1e>;
				focaltech,fw-upgrade-id1 = <0x11>;
				focaltech,fw-upgrade-id2 = <0x11>;
				focaltech,fw-delay-readid-ms = <0xa>;
				focaltech,fw-delay-era-flsh-ms = <0x7d0>;
				focaltech,fw-auto-cal;
				focaltech,ignore-id-check;
			};
		};

		gen-vkeys {
			compatible = "qcom,gen-vkeys";
			label = "ft5x06_ts";
			qcom,disp-maxx = <0x438>;
			qcom,disp-maxy = <0x780>;
			qcom,panel-maxx = <0x438>;
			qcom,panel-maxy = <0x832>;
			qcom,key-codes = <0x8b 0xac 0x9e>;
			qcom,y-offset = <0x0>;
		};

		sound {
			compatible = "qcom,msm8x16-audio-codec";
			qcom,model = "msm8939-snd-card-skuk";
			qcom,msm-snd-card-id = <0x0>;
			qcom,msm-codec-type = "internal";
			qcom,msm-ext-pa = "primary";
			qcom,msm-mbhc-hphl-swh = <0x1>;
			qcom,msm-mbhc-gnd-swh = <0x0>;
			qcom,msm-micbias1-ext-cap;
			qcom,msm-hs-micbias-type = "internal";
			qcom,audio-routing = "RX_BIAS", "MCLK", "SPK_RX_BIAS", "MCLK", "INT_LDO_H", "MCLK", "MIC BIAS External", "Handset Mic", "MIC BIAS Internal2", "Headset Mic", "MIC BIAS External", "Secondary Mic", "AMIC1", "MIC BIAS External", "AMIC2", "MIC BIAS Internal2", "AMIC3", "MIC BIAS External";
			pinctrl-names = "cdc_lines_act", "cdc_lines_sus";
			pinctrl-0 = <0x98>;
			pinctrl-1 = <0x99>;
		};
	};

	regulator-s1-corner {
		compatible = "qcom,stub-regulator";
		regulator-name = "8916_s1_corner";
		qcom,hpm-min-load = <0x186a0>;
		regulator-min-microvolt = <0x1>;
		regulator-max-microvolt = <0x7>;
		linux,phandle = <0x66>;
		phandle = <0x66>;
	};

	regulator-s1-corner-ao {
		compatible = "qcom,stub-regulator";
		regulator-name = "8916_s1_corner_ao";
		qcom,hpm-min-load = <0x186a0>;
		regulator-min-microvolt = <0x1>;
		regulator-max-microvolt = <0x7>;
	};

	regulator-s2-corner {
		compatible = "qcom,stub-regulator";
		regulator-name = "8916_s2_corner";
		qcom,hpm-min-load = <0x186a0>;
		regulator-min-microvolt = <0x1>;
		regulator-max-microvolt = <0x7>;
	};

	regulator-s2-corner-ao {
		compatible = "qcom,stub-regulator";
		regulator-name = "8916_s2_corner_ao";
		qcom,hpm-min-load = <0x186a0>;
		regulator-min-microvolt = <0x1>;
		regulator-max-microvolt = <0x7>;
	};

	regulator-apc-corner {
		compatible = "qcom,stub-regulator";
		regulator-name = "apc_corner";
		regulator-min-microvolt = <0x1>;
		regulator-max-microvolt = <0x3>;
	};

	regulator-l3-corner {
		compatible = "qcom,stub-regulator";
		regulator-name = "8916_l3_corner";
		qcom,hpm-min-load = <0x2710>;
		regulator-min-microvolt = <0x1>;
		regulator-max-microvolt = <0x7>;
	};

	regulator-l3-corner-ao {
		compatible = "qcom,stub-regulator";
		regulator-name = "8916_l3_corner_ao";
		qcom,hpm-min-load = <0x2710>;
		regulator-min-microvolt = <0x1>;
		regulator-max-microvolt = <0x7>;
	};

	regulator-l7-ao {
		compatible = "qcom,stub-regulator";
		regulator-name = "8916_l7_ao";
		regulator-min-microvolt = <0x1b7740>;
		regulator-max-microvolt = <0x1b7740>;
	};
};
